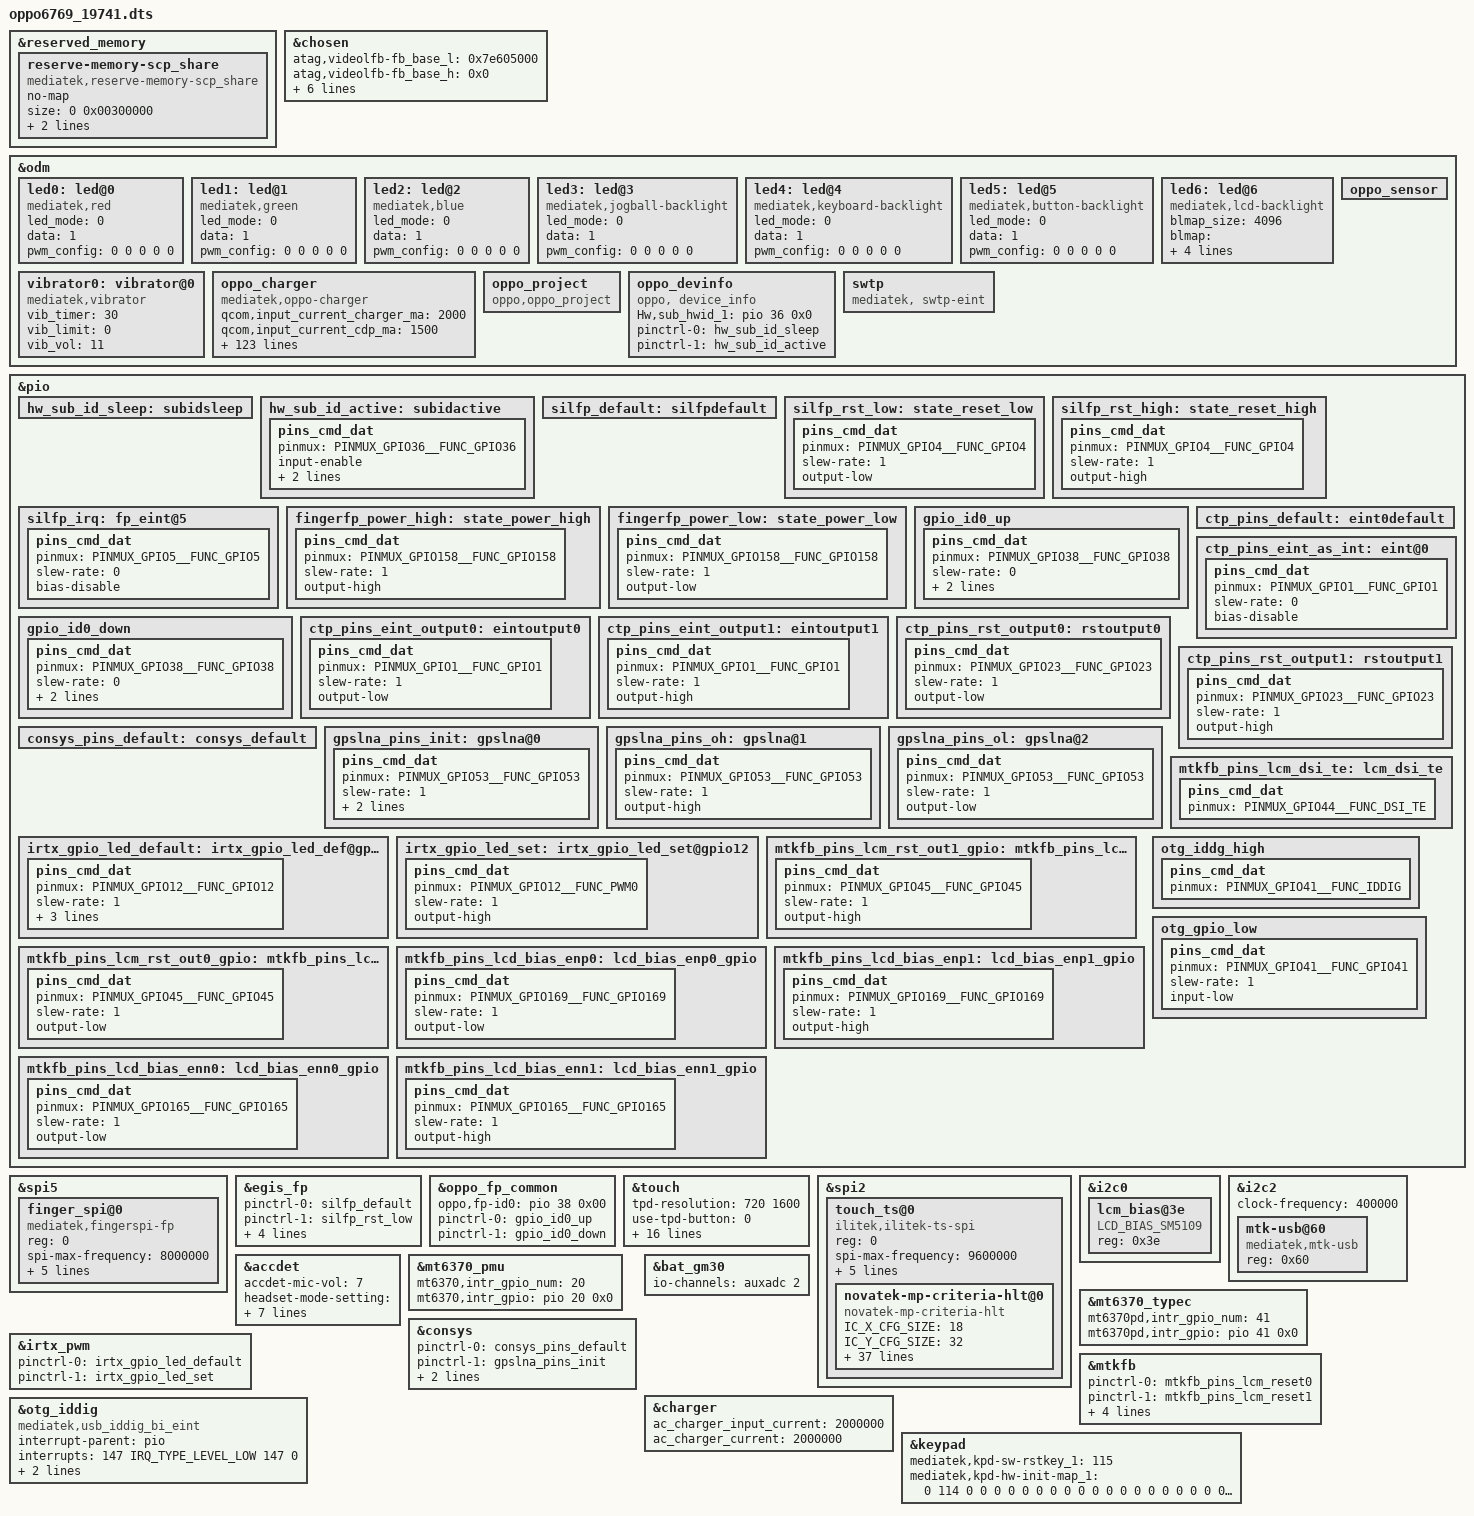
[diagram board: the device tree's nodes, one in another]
/*
 * Copyright (C) 2019 MediaTek Inc.
 *
 * This program is free software; you can redistribute it and/or modify
 * it under the terms of the GNU General Public License version 2 as
 * published by the Free Software Foundation.
 *
 * This program is distributed in the hope that it will be useful,
 * but WITHOUT ANY WARRANTY; without even the implied warranty of
 * MERCHANTABILITY or FITNESS FOR A PARTICULAR PURPOSE.
 * See http://www.gnu.org/licenses/gpl-2.0.html for more details.
 */

/dts-v1/;
/plugin/;
#include <dt-bindings/interrupt-controller/irq.h>
#include <dt-bindings/interrupt-controller/arm-gic.h>
#include <dt-bindings/pinctrl/mt6768-pinfunc.h>

&reserved_memory {
	reserve-memory-scp_share {
		compatible = "mediatek,reserve-memory-scp_share";
		no-map;
		size = <0 0x00300000>;
		alignment = <0 0x1000000>;
		alloc-ranges = <0 0x40000000 0 0x50000000>;
	};
};

/* chosen */
&chosen {

	atag,videolfb-fb_base_l = <0x7e605000>;
	atag,videolfb-fb_base_h = <0x0>;
	atag,videolfb-islcmfound = <1>;
	atag,videolfb-islcm_inited = <0>;
	atag,videolfb-fps= <6000>;
	atag,videolfb-vramSize= <0x017e8000>;
	atag,videolfb-lcmname=
		"hx83112b_fhdp_dsi_cmd_auo_rt5081_drv";
};

&odm {
	led0:led@0 {
		compatible = "mediatek,red";
		led_mode = <0>;
		data = <1>;
		pwm_config = <0 0 0 0 0>;
	};
	led1:led@1 {
		compatible = "mediatek,green";
		led_mode = <0>;
		data = <1>;
		pwm_config = <0 0 0 0 0>;
	};
	led2:led@2 {
		compatible = "mediatek,blue";
		led_mode = <0>;
		data = <1>;
		pwm_config = <0 0 0 0 0>;
	};
	led3:led@3 {
		compatible = "mediatek,jogball-backlight";
		led_mode = <0>;
		data = <1>;
		pwm_config = <0 0 0 0 0>;
	};
	led4:led@4 {
		compatible = "mediatek,keyboard-backlight";
		led_mode = <0>;
		data = <1>;
		pwm_config = <0 0 0 0 0>;
	};
	led5:led@5 {
		compatible = "mediatek,button-backlight";
		led_mode = <0>;
		data = <1>;
		pwm_config = <0 0 0 0 0>;
	};
	led6:led@6 {
		compatible = "mediatek,lcd-backlight";
		blmap_size = <4096>;
		blmap = <
			0 1 2 3 4 5 6 7 8 9 10 11 12 13
			14 17 21 26 31 38 44 51 59 67 76 85 95 105
			115 126 137 148 160 172 184 196 208 220 233 245 258 270
			283 295 307 319 331 343 355 366 377 388 398 408 418 427
			436 445 454 462 471 479 487 495 503 510 518 524 531 537
			543 548 553 557 562 565 569 573 576 580 583 586 590 593
			597 600 604 607 610 614 617 621 624 628 631 635 638 641
			645 648 652 655 658 662 665 668 672 675 678 682 685 688
			691 695 698 701 704 707 711 714 717 720 723 726 729 732
			735 738 741 744 747 750 753 756 759 762 765 768 771 774
			777 779 782 785 788 790 793 796 798 801 804 806 809 812
			814 817 819 822 824 827 829 832 834 836 839 841 843 846
			848 850 853 855 857 859 862 864 866 868 871 873 875 877
			880 882 884 886 889 891 893 895 898 900 902 904 906 908
			911 913 915 917 919 921 924 926 928 930 932 934 936 939
			941 943 945 947 949 951 953 955 958 960 962 964 966 968
			970 972 974 976 978 980 982 984 986 988 990 992 994 996
			998 1000 1002 1004 1006 1008 1010 1012 1014 1016 1018 1020 1022 1024
			1026 1028 1030 1032 1034 1036 1038 1040 1042 1044 1045 1047 1049 1051
			1053 1055 1057 1059 1061 1063 1064 1066 1068 1070 1072 1074 1076 1077
			1079 1081 1083 1085 1087 1089 1090 1092 1094 1096 1098 1099 1101 1103
			1105 1107 1109 1110 1112 1114 1116 1117 1119 1121 1123 1125 1126 1128
			1130 1132 1133 1135 1137 1139 1140 1142 1144 1146 1147 1149 1151 1152
			1154 1156 1158 1159 1161 1163 1164 1166 1168 1170 1171 1173 1175 1176
			1178 1180 1181 1183 1185 1186 1188 1190 1191 1193 1195 1196 1198 1200
			1201 1203 1204 1206 1208 1209 1211 1213 1214 1216 1217 1219 1221 1222
			1224 1226 1227 1229 1230 1232 1233 1235 1237 1238 1240 1241 1243 1245
			1246 1248 1249 1251 1252 1254 1256 1257 1259 1260 1262 1263 1265 1266
			1268 1269 1271 1272 1274 1276 1277 1279 1280 1282 1283 1285 1286 1288
			1289 1291 1292 1294 1295 1297 1298 1300 1301 1303 1304 1306 1307 1309
			1310 1312 1313 1315 1316 1318 1319 1321 1322 1323 1325 1326 1328 1329
			1331 1332 1334 1335 1337 1338 1339 1341 1342 1344 1345 1347 1348 1350
			1351 1352 1354 1355 1357 1358 1360 1361 1362 1364 1365 1367 1368 1370
			1371 1372 1374 1375 1377 1378 1379 1381 1382 1384 1385 1386 1388 1389
			1391 1392 1393 1395 1396 1398 1399 1400 1402 1403 1405 1406 1407 1409
			1410 1412 1413 1414 1416 1417 1418 1420 1421 1423 1424 1425 1427 1428
			1429 1431 1432 1433 1435 1436 1438 1439 1440 1442 1443 1444 1446 1447
			1448 1450 1451 1452 1454 1455 1457 1458 1459 1461 1462 1463 1465 1466
			1467 1469 1470 1471 1473 1474 1475 1477 1478 1479 1481 1482 1483 1485
			1486 1487 1489 1490 1491 1493 1494 1495 1497 1498 1499 1501 1502 1503
			1505 1506 1507 1509 1510 1511 1513 1514 1515 1517 1518 1519 1521 1522
			1523 1525 1526 1527 1529 1530 1531 1533 1534 1535 1537 1538 1539 1541
			1542 1543 1545 1546 1547 1549 1550 1551 1553 1554 1555 1557 1558 1559
			1561 1562 1563 1565 1566 1567 1569 1570 1571 1573 1574 1575 1577 1578
			1579 1581 1582 1583 1585 1586 1587 1589 1590 1591 1593 1594 1595 1597
			1598 1599 1601 1602 1603 1605 1606 1608 1609 1610 1612 1613 1614 1616
			1617 1618 1620 1621 1622 1624 1625 1626 1628 1629 1630 1632 1633 1635
			1636 1637 1639 1640 1641 1643 1644 1645 1647 1648 1649 1651 1652 1653
			1655 1656 1657 1658 1660 1661 1662 1663 1665 1666 1667 1668 1670 1671
			1672 1673 1674 1676 1677 1678 1679 1680 1682 1683 1684 1685 1686 1687
			1688 1690 1691 1692 1693 1694 1695 1696 1697 1699 1700 1701 1702 1703
			1704 1705 1706 1707 1708 1709 1711 1712 1713 1714 1715 1716 1717 1718
			1719 1720 1721 1722 1723 1724 1725 1726 1727 1728 1730 1731 1732 1733
			1734 1735 1736 1737 1738 1739 1740 1741 1742 1743 1744 1745 1746 1747
			1748 1749 1750 1751 1752 1753 1754 1755 1756 1757 1758 1759 1760 1761
			1762 1763 1764 1765 1767 1768 1769 1770 1771 1772 1773 1774 1775 1776
			1777 1778 1779 1780 1781 1782 1783 1784 1785 1786 1787 1789 1790 1791
			1792 1793 1794 1795 1796 1797 1798 1799 1800 1801 1802 1803 1804 1805
			1806 1808 1809 1810 1811 1812 1813 1814 1815 1816 1817 1818 1819 1820
			1821 1822 1823 1824 1825 1827 1828 1829 1830 1831 1832 1833 1834 1835
			1836 1837 1838 1839 1840 1841 1842 1843 1844 1845 1847 1848 1849 1850
			1851 1852 1853 1854 1855 1856 1857 1858 1859 1860 1861 1862 1863 1864
			1865 1866 1867 1868 1870 1871 1872 1873 1874 1875 1876 1877 1878 1879
			1880 1881 1882 1883 1884 1885 1886 1887 1888 1889 1890 1891 1892 1893
			1894 1895 1896 1897 1898 1899 1901 1902 1903 1904 1905 1906 1907 1908
			1909 1910 1911 1912 1913 1914 1915 1916 1917 1918 1919 1920 1921 1922
			1923 1924 1925 1926 1927 1928 1929 1930 1931 1932 1933 1934 1935 1936
			1937 1938 1939 1940 1941 1942 1943 1944 1945 1946 1947 1948 1949 1950
			1951 1952 1953 1954 1955 1956 1957 1958 1959 1960 1961 1962 1963 1964
			1964 1965 1966 1967 1968 1969 1970 1971 1972 1973 1974 1975 1976 1977
			1978 1979 1980 1981 1982 1983 1984 1985 1986 1986 1987 1988 1989 1990
			1991 1992 1993 1994 1995 1996 1997 1998 1999 2000 2001 2001 2002 2003
			2004 2005 2006 2007 2008 2009 2010 2011 2012 2012 2013 2014 2015 2016
			2017 2018 2019 2020 2021 2021 2022 2023 2024 2025 2026 2027 2028 2029
			2029 2030 2031 2032 2033 2034 2035 2036 2036 2037 2038 2039 2040 2041
			2042 2042 2043 2044 2045 2046 2047 2048 2048 2049 2050 2051 2052 2053
			2053 2054 2055 2056 2057 2058 2058 2059 2060 2061 2062 2062 2063 2064
			2065 2066 2067 2067 2068 2069 2070 2071 2071 2072 2073 2074 2075 2075
			2076 2077 2078 2079 2079 2080 2081 2082 2082 2083 2084 2085 2086 2086
			2087 2088 2089 2089 2090 2091 2092 2092 2093 2094 2095 2096 2096 2097
			2098 2099 2099 2100 2101 2102 2102 2103 2104 2105 2105 2106 2107 2108
			2108 2109 2110 2110 2111 2112 2113 2113 2114 2115 2116 2116 2117 2118
			2119 2119 2120 2121 2121 2122 2123 2124 2124 2125 2126 2126 2127 2128
			2129 2129 2130 2131 2131 2132 2133 2134 2134 2135 2136 2136 2137 2138
			2139 2139 2140 2141 2141 2142 2143 2144 2144 2145 2146 2146 2147 2148
			2148 2149 2150 2151 2151 2152 2153 2153 2154 2155 2155 2156 2157 2157
			2158 2159 2160 2160 2161 2162 2162 2163 2164 2164 2165 2166 2166 2167
			2168 2169 2169 2170 2171 2171 2172 2173 2173 2174 2175 2175 2176 2177
			2177 2178 2179 2179 2180 2181 2182 2182 2183 2184 2184 2185 2186 2186
			2187 2188 2188 2189 2190 2190 2191 2192 2192 2193 2194 2195 2195 2196
			2197 2197 2198 2199 2199 2200 2201 2201 2202 2203 2203 2204 2205 2206
			2206 2207 2208 2208 2209 2210 2210 2211 2212 2212 2213 2214 2215 2215
			2216 2217 2217 2218 2219 2219 2220 2221 2221 2222 2223 2224 2224 2225
			2226 2226 2227 2228 2228 2229 2230 2231 2231 2232 2233 2233 2234 2235
			2236 2236 2237 2238 2238 2239 2240 2240 2241 2242 2243 2243 2244 2245
			2245 2246 2247 2248 2248 2249 2250 2251 2251 2252 2253 2253 2254 2255
			2256 2256 2257 2258 2259 2259 2260 2261 2261 2262 2263 2264 2264 2265
			2266 2267 2267 2268 2269 2270 2270 2271 2272 2273 2273 2274 2275 2276
			2276 2277 2278 2279 2279 2280 2281 2282 2282 2283 2284 2285 2285 2286
			2287 2288 2288 2289 2290 2291 2291 2292 2293 2294 2294 2295 2296 2297
			2297 2298 2299 2300 2300 2301 2302 2303 2303 2304 2305 2306 2306 2307
			2308 2309 2309 2310 2311 2312 2313 2313 2314 2315 2316 2316 2317 2318
			2319 2319 2320 2321 2322 2322 2323 2324 2325 2326 2326 2327 2328 2329
			2329 2330 2331 2332 2332 2333 2334 2335 2336 2336 2337 2338 2339 2339
			2340 2341 2342 2342 2343 2344 2345 2346 2346 2347 2348 2349 2349 2350
			2351 2352 2353 2353 2354 2355 2356 2356 2357 2358 2359 2359 2360 2361
			2362 2363 2363 2364 2365 2366 2366 2367 2368 2369 2370 2370 2371 2372
			2373 2373 2374 2375 2376 2376 2377 2378 2379 2380 2380 2381 2382 2383
			2383 2384 2385 2386 2387 2387 2388 2389 2390 2390 2391 2392 2393 2394
			2394 2395 2396 2397 2397 2398 2399 2400 2400 2401 2402 2403 2404 2404
			2405 2406 2407 2407 2408 2409 2410 2411 2411 2412 2413 2414 2414 2415
			2416 2417 2417 2418 2419 2420 2421 2421 2422 2423 2424 2424 2425 2426
			2427 2427 2428 2429 2430 2430 2431 2432 2433 2434 2434 2435 2436 2437
			2437 2438 2439 2440 2440 2441 2442 2443 2443 2444 2445 2446 2446 2447
			2448 2449 2450 2450 2451 2452 2453 2453 2454 2455 2456 2456 2457 2458
			2459 2459 2460 2461 2462 2462 2463 2464 2465 2465 2466 2467 2468 2468
			2469 2470 2471 2471 2472 2473 2474 2474 2475 2476 2477 2477 2478 2479
			2480 2480 2481 2482 2482 2483 2484 2485 2485 2486 2487 2488 2488 2489
			2490 2491 2491 2492 2493 2493 2494 2495 2496 2496 2497 2498 2499 2499
			2500 2501 2502 2502 2503 2504 2504 2505 2506 2507 2507 2508 2509 2509
			2510 2511 2512 2512 2513 2514 2514 2515 2516 2517 2517 2518 2519 2519
			2520 2521 2522 2522 2523 2524 2524 2525 2526 2527 2527 2528 2529 2529
			2530 2531 2531 2532 2533 2534 2534 2535 2536 2536 2537 2538 2538 2539
			2540 2540 2541 2542 2542 2543 2544 2545 2545 2546 2547 2547 2548 2549
			2549 2550 2551 2551 2552 2553 2553 2554 2555 2555 2556 2557 2557 2558
			2559 2559 2560 2561 2561 2562 2563 2563 2564 2565 2565 2566 2567 2567
			2568 2569 2569 2570 2571 2571 2572 2572 2573 2574 2574 2575 2576 2576
			2577 2578 2578 2579 2580 2580 2581 2581 2582 2583 2583 2584 2585 2585
			2586 2587 2587 2588 2588 2589 2590 2590 2591 2592 2592 2593 2593 2594
			2595 2595 2596 2597 2597 2598 2598 2599 2600 2600 2601 2602 2602 2603
			2603 2604 2605 2605 2606 2607 2607 2608 2608 2609 2610 2610 2611 2611
			2612 2613 2613 2614 2615 2615 2616 2616 2617 2618 2618 2619 2619 2620
			2621 2621 2622 2622 2623 2624 2624 2625 2625 2626 2627 2627 2628 2628
			2629 2630 2630 2631 2631 2632 2633 2633 2634 2634 2635 2636 2636 2637
			2637 2638 2639 2639 2640 2640 2641 2642 2642 2643 2643 2644 2645 2645
			2646 2646 2647 2648 2648 2649 2649 2650 2650 2651 2652 2652 2653 2653
			2654 2655 2655 2656 2656 2657 2657 2658 2659 2659 2660 2660 2661 2661
			2662 2663 2663 2664 2664 2665 2666 2666 2667 2667 2668 2668 2669 2670
			2670 2671 2671 2672 2672 2673 2674 2674 2675 2675 2676 2676 2677 2677
			2678 2679 2679 2680 2680 2681 2681 2682 2683 2683 2684 2684 2685 2685
			2686 2687 2687 2688 2688 2689 2689 2690 2690 2691 2692 2692 2693 2693
			2694 2694 2695 2695 2696 2697 2697 2698 2698 2699 2699 2700 2700 2701
			2702 2702 2703 2703 2704 2704 2705 2705 2706 2706 2707 2708 2708 2709
			2709 2710 2710 2711 2711 2712 2712 2713 2714 2714 2715 2715 2716 2716
			2717 2717 2718 2718 2719 2719 2720 2721 2721 2722 2722 2723 2723 2724
			2724 2725 2725 2726 2726 2727 2728 2728 2729 2729 2730 2730 2731 2731
			2732 2732 2733 2733 2734 2734 2735 2736 2736 2737 2737 2738 2738 2739
			2739 2740 2740 2741 2741 2742 2742 2743 2743 2744 2744 2745 2745 2746
			2747 2747 2748 2748 2749 2749 2750 2750 2751 2751 2752 2752 2753 2753
			2754 2754 2755 2755 2756 2756 2757 2757 2758 2758 2759 2760 2760 2761
			2761 2762 2762 2763 2763 2764 2764 2765 2765 2766 2766 2767 2767 2768
			2768 2769 2769 2770 2770 2771 2771 2772 2772 2773 2773 2774 2774 2775
			2775 2776 2776 2777 2777 2778 2778 2779 2779 2780 2780 2781 2781 2782
			2782 2783 2783 2784 2784 2785 2785 2786 2786 2787 2787 2788 2788 2789
			2789 2790 2790 2791 2791 2792 2792 2793 2793 2794 2794 2795 2795 2796
			2796 2797 2797 2798 2798 2799 2799 2800 2800 2801 2801 2802 2802 2803
			2803 2804 2804 2805 2805 2806 2806 2807 2807 2808 2808 2809 2809 2810
			2810 2811 2811 2812 2812 2813 2813 2814 2814 2815 2815 2816 2816 2817
			2817 2818 2818 2819 2819 2819 2820 2820 2821 2821 2822 2822 2823 2823
			2824 2824 2825 2825 2826 2826 2827 2827 2828 2828 2829 2829 2830 2830
			2831 2831 2832 2832 2833 2833 2833 2834 2834 2835 2835 2836 2836 2837
			2837 2838 2838 2839 2839 2840 2840 2841 2841 2842 2842 2843 2843 2844
			2844 2844 2845 2845 2846 2846 2847 2847 2848 2848 2849 2849 2850 2850
			2851 2851 2852 2852 2853 2853 2853 2854 2854 2855 2855 2856 2856 2857
			2857 2858 2858 2859 2859 2860 2860 2861 2861 2861 2862 2862 2863 2863
			2864 2864 2865 2865 2866 2866 2867 2867 2868 2868 2869 2869 2869 2870
			2870 2871 2871 2872 2872 2873 2873 2874 2874 2875 2875 2876 2876 2876
			2877 2877 2878 2878 2879 2879 2880 2880 2881 2881 2882 2882 2882 2883
			2883 2884 2884 2885 2885 2886 2886 2887 2887 2888 2888 2889 2889 2889
			2890 2890 2891 2891 2892 2892 2893 2893 2894 2894 2895 2895 2895 2896
			2896 2897 2897 2898 2898 2899 2899 2900 2900 2900 2901 2901 2902 2902
			2903 2903 2904 2904 2905 2905 2906 2906 2906 2907 2907 2908 2908 2909
			2909 2910 2910 2911 2911 2911 2912 2912 2913 2913 2914 2914 2915 2915
			2916 2916 2917 2917 2917 2918 2918 2919 2919 2920 2920 2921 2921 2922
			2922 2922 2923 2923 2924 2924 2925 2925 2926 2926 2927 2927 2927 2928
			2928 2929 2929 2930 2930 2931 2931 2932 2932 2932 2933 2933 2934 2934
			2935 2935 2936 2936 2937 2937 2937 2938 2938 2939 2939 2940 2940 2941
			2941 2942 2942 2942 2943 2943 2944 2944 2945 2945 2946 2946 2947 2947
			2947 2948 2948 2949 2949 2950 2950 2951 2951 2952 2952 2952 2953 2953
			2954 2954 2955 2955 2956 2956 2957 2957 2957 2958 2958 2959 2959 2960
			2960 2961 2961 2961 2962 2962 2963 2963 2964 2964 2965 2965 2966 2966
			2966 2967 2967 2968 2968 2969 2969 2970 2970 2971 2971 2971 2972 2972
			2973 2973 2974 2974 2975 2975 2976 2976 2976 2977 2977 2978 2978 2979
			2979 2980 2980 2981 2981 2981 2982 2982 2983 2983 2984 2984 2985 2985
			2986 2986 2986 2987 2987 2988 2988 2989 2989 2990 2990 2990 2991 2991
			2992 2992 2993 2993 2994 2994 2995 2995 2995 2996 2996 2997 2997 2998
			2998 2999 2999 3000 3000 3000 3001 3001 3002 3002 3003 3003 3004 3004
			3005 3005 3006 3006 3006 3007 3007 3008 3008 3009 3009 3010 3010 3011
			3011 3011 3012 3012 3013 3013 3014 3014 3015 3015 3016 3016 3016 3017
			3017 3018 3018 3019 3019 3020 3020 3021 3021 3021 3022 3022 3023 3023
			3024 3024 3025 3025 3026 3026 3027 3027 3027 3028 3028 3029 3029 3030
			3030 3031 3031 3032 3032 3032 3033 3033 3034 3034 3035 3035 3036 3036
			3037 3037 3038 3038 3038 3039 3039 3040 3040 3041 3041 3042 3042 3043
			3043 3044 3044 3044 3045 3045 3046 3046 3047 3047 3048 3048 3049 3049
			3050 3050 3051 3051 3051 3052 3052 3053 3053 3054 3054 3055 3055 3056
			3056 3057 3057 3057 3058 3058 3059 3059 3060 3060 3061 3061 3062 3062
			3063 3063 3064 3064 3064 3065 3065 3066 3066 3067 3067 3068 3068 3069
			3069 3070 3070 3071 3071 3072 3072 3072 3073 3073 3074 3074 3075 3075
			3076 3076 3077 3077 3078 3078 3079 3079 3080 3080 3080 3081 3081 3082
			3082 3083 3083 3084 3084 3085 3085 3086 3086 3087 3087 3088 3088 3089
			3089 3090 3090 3090 3091 3091 3092 3092 3093 3093 3094 3094 3095 3095
			3096 3096 3097 3097 3098 3098 3099 3099 3100 3100 3101 3101 3101 3102
			3102 3103 3103 3104 3104 3105 3105 3106 3106 3107 3107 3108 3108 3109
			3109 3110 3110 3111 3111 3112 3112 3113 3113 3114 3114 3115 3115 3116
			3116 3117 3117 3117 3118 3118 3119 3119 3120 3120 3121 3121 3122 3122
			3123 3123 3124 3124 3125 3125 3126 3126 3127 3127 3128 3128 3129 3129
			3130 3130 3131 3131 3132 3132 3133 3133 3134 3134 3135 3135 3136 3136
			3137 3137 3138 3138 3139 3139 3140 3140 3141 3141 3142 3142 3143 3143
			3144 3144 3145 3145 3146 3146 3147 3147 3148 3148 3149 3149 3150 3150
			3151 3151 3152 3152 3153 3153 3154 3154 3155 3155 3156 3156 3157 3157
			3158 3158 3159 3159 3160 3160 3161 3161 3162 3162 3163 3163 3164 3164
			3165 3165 3166 3166 3167 3167 3168 3168 3169 3170 3170 3171 3171 3172
			3172 3173 3173 3174 3174 3175 3175 3176 3176 3177 3177 3178 3178 3179
			3179 3180 3180 3181 3181 3182 3182 3183 3183 3184 3185 3185 3186 3186
			3187 3187 3188 3188 3189 3189 3190 3190 3191 3191 3192 3192 3193 3193
			3194 3195 3195 3196 3196 3197 3197 3198 3198 3199 3199 3200 3200 3201
			3201 3202 3202 3203 3204 3204 3205 3205 3206 3206 3207 3207 3208 3208
			3209 3209 3210 3211 3211 3212 3212 3213 3213 3214 3214 3215 3215 3216
			3216 3217 3218 3218 3219 3219 3220 3220 3221 3221 3222 3222 3223 3224
			3224 3225 3225 3226 3226 3227 3227 3228 3228 3229 3230 3230 3231 3231
			3232 3232 3233 3233 3234 3235 3235 3236 3236 3237 3237 3238 3238 3239
			3240 3240 3241 3241 3242 3242 3243 3243 3244 3245 3245 3246 3246 3247
			3247 3248 3248 3249 3250 3250 3251 3251 3252 3252 3253 3254 3254 3255
			3255 3256 3256 3257 3258 3258 3259 3259 3260 3260 3261 3261 3262 3263
			3263 3264 3264 3265 3266 3266 3267 3267 3268 3268 3269 3270 3270 3271
			3271 3272 3272 3273 3274 3274 3275 3275 3276 3276 3277 3278 3278 3279
			3279 3280 3281 3281 3282 3282 3283 3284 3284 3285 3285 3286 3286 3287
			3288 3288 3289 3289 3290 3291 3291 3292 3292 3293 3294 3294 3295 3295
			3296 3297 3297 3298 3298 3299 3300 3300 3301 3301 3302 3303 3303 3304
			3304 3305 3306 3306 3307 3307 3308 3309 3309 3310 3310 3311 3312 3312
			3313 3313 3314 3315 3315 3316 3316 3317 3318 3318 3319 3320 3320 3321
			3321 3322 3323 3323 3324 3324 3325 3326 3326 3327 3328 3328 3329 3329
			3330 3331 3331 3332 3332 3333 3334 3334 3335 3336 3336 3337 3337 3338
			3339 3339 3340 3341 3341 3342 3343 3343 3344 3344 3345 3346 3346 3347
			3348 3348 3349 3349 3350 3351 3351 3352 3353 3353 3354 3355 3355 3356
			3357 3357 3358 3358 3359 3360 3360 3361 3362 3362 3363 3364 3364 3365
			3366 3366 3367 3368 3368 3369 3369 3370 3371 3371 3372 3373 3373 3374
			3375 3375 3376 3377 3377 3378 3379 3379 3380 3381 3381 3382 3383 3383
			3384 3385 3385 3386 3387 3387 3388 3389 3389 3390 3391 3391 3392 3393
			3393 3394 3395 3395 3396 3397 3397 3398 3399 3399 3400 3401 3401 3402
			3403 3403 3404 3405 3405 3406 3407 3407 3408 3409 3410 3410 3411 3412
			3412 3413 3414 3414 3415 3416 3416 3417 3418 3418 3419 3420 3421 3421
			3422 3423 3423 3424 3425 3425 3426 3427 3427 3428 3429 3430 3430 3431
			3432 3432 3433 3434 3434 3435 3436 3437 3437 3438 3439 3439 3440 3441
			3442 3442 3443 3444 3444 3445 3446 3447 3447 3448 3449 3449 3450 3451
			3452 3452 3453 3454 3454 3455 3456 3457 3457 3458 3459 3459 3460 3461
			3462 3462 3463 3464 3465 3465 3466 3467 3467 3468 3469 3470 3470 3471
			3472 3473 3473 3474 3475 3476 3476 3477 3478 3479 3479 3480 3481 3481
			3482 3483 3484 3484 3485 3486 3487 3487 3488 3489 3490 3490 3491 3492
			3493 3493 3494 3495 3496 3496 3497 3498 3499 3499 3500 3501 3502 3503
			3503 3504 3505 3506 3506 3507 3508 3509 3509 3510 3511 3512 3512 3513
			3514 3515 3516 3517 3518 3519 3520 3521 3522 3523 3524 3525 3526 3527
			3528 3529 3530 3531 3532 3533 3534 3535 3536 3537 3538 3539 3540 3541
			3542 3543 3544 3545 3546 3547 3548 3549 3550 3551 3552 3553 3554 3555
			3556 3557 3558 3559 3560 3561 3562 3563 3564 3565 3566 3567 3568 3569
			3570 3571 3572 3573 3574 3575 3576 3577 3578 3579 3580 3581 3582 3583
			3584 3585 3586 3587 3588 3589 3590 3591 3592 3593 3594 3595 3596 3597
			3598 3599 3600 3601 3602 3603 3604 3605 3606 3607 3608 3609 3610 3611
			3612 3613 3614 3615 3616 3617 3618 3619 3620 3621 3622 3623 3624 3625
			3626 3627 3628 3629 3630 3631 3632 3633 3634 3635 3636 3637 3638 3639
			3640 3641 3642 3643 3644 3645 3646 3647 3648 3649 3650 3651 3652 3653
			3654 3655 3656 3657 3658 3659 3660 3661 3662 3663 3664 3665 3666 3667
			3668 3669 3670 3671 3672 3673 3674 3675 3676 3677 3678 3679 3680 3681
			3682 3683 3684 3685 3686 3687 3688 3689 3690 3691 3692 3693 3694 3695
			3696 3697 3698 3699 3700 3701 3702 3703 3704 3705 3706 3707 3708 3709
			3710 3711 3712 3713 3714 3715 3716 3717 3718 3719 3720 3721 3722 3723
			3724 3725 3726 3727 3728 3729 3730 3731 3732 3733 3734 3735 3736 3737
			3738 3739 3740 3741 3742 3743 3744 3745 3746 3747 3748 3749 3750 3751
			3752 3753 3754 3755 3756 3757 3758 3759 3760 3761 3762 3763 3764 3765
			3766 3767 3768 3769 3770 3771 3772 3773 3774 3775 3776 3777 3778 3779
			3780 3781 3782 3783 3784 3785 3786 3787 3788 3789 3790 3791 3792 3793
			3794 3795 3796 3797 3798 3799 3800 3801 3802 3803 3804 3805 3806 3807
			3808 3809 3810 3811 3812 3813 3814 3815 3816 3817 3818 3819 3820 3821
			3822 3823 3824 3825 3826 3827 3828 3829 3830 3831 3832 3833 3834 3835
			3836 3837 3838 3839 3840 3841 3842 3843 3844 3845 3846 3847 3848 3849
			3850 3851 3852 3853 3854 3855 3856 3857 3858 3859 3860 3861 3862 3863
			3864 3865 3866 3867 3868 3869 3870 3871 3872 3873 3874 3875 3876 3877
			3878 3879 3880 3881 3882 3883 3884 3885 3886 3887 3888 3889 3890 3891
			3892 3893 3894 3895 3896 3897 3898 3899 3900 3901 3902 3903 3904 3905
			3906 3907 3908 3909 3910 3911 3912 3913 3914 3915 3916 3917 3918 3919
			3920 3921 3922 3923 3924 3925 3926 3927 3928 3929 3930 3931 3932 3933
			3934 3935 3936 3937 3938 3939 3940 3941 3942 3943 3944 3945 3946 3947
			3948 3949 3950 3951 3952 3953 3954 3955 3956 3957 3958 3959 3960 3961
			3962 3963 3964 3965 3966 3967 3968 3969 3970 3971 3972 3973 3974 3975
			3976 3977 3978 3979 3980 3981 3982 3983 3984 3985 3986 3987 3988 3989
			3990 3991 3992 3993 3994 3995 3996 3997 3998 3999 4000 4001 4002 4003
			4004 4005 4006 4007 4008 4009 4010 4011 4012 4013 4014 4015 4016 4017
			4018 4019 4020 4021 4022 4023 4024 4025 4026 4027 4028 4029 4030 4031
			4032 4033 4034 4035 4036 4037 4038 4039 4040 4041 4042 4043 4044 4045
			4046 4047 4048 4049 4050 4051 4052 4053 4054 4055 4056 4057 4058 4059
			4060 4061 4062 4063 4064 4065 4066 4067 4068 4069 4070 4071 4072 4073
			4074 4075 4076 4077 4078 4079 4080 4081 4082 4083 4084 4085 4086 4087
			4088 4089 4090 4091 4092 4093 4094 4095
		>;
		led_mode = <4>;
		data = <1>;
		pwm_config = <0 3 0 0 0>;
	};
	vibrator0:vibrator@0 {
		compatible = "mediatek,vibrator";
		/*
		vib_timer = <25>;
		vib_limit = <9>;
		vib_vol= <9>;
		*/
		vib_timer = <30>; /*xing.xiong@BSP.Kernel.Driver, 2018/12/08, Add for vibrator*/
		vib_limit = <0>;
		vib_vol= <11>;
	};
//#ifdef ODM_WT_EDIT
/*Sidong.Zhao@ODM_WT.BSP.CHG 2019/11/4,add oppo charge framework*/
	oppo_charger: oppo_charger {
		compatible = "mediatek,oppo-charger";
		//pinctrl-names = "default", "charger_gpio_as_output_low", "charger_gpio_as_output_high", "ship_sleep", "ship_active", "shortc_active";
		//pinctrl-0 = <&charger_pins_default>;
		//pinctrl-1 = <&charger_pins_eint_output0>;
		//pinctrl-2 = <&charger_pins_eint_output1>;
		//pinctrl-3 = <&ship_sleep_gpio>;
		//pinctrl-4 = <&ship_active_gpio>;
		//pinctrl-5 = <&shortc_active_gpio>;

		//for oppo chg framework:
		qcom,input_current_charger_ma = <2000>;
		qcom,input_current_cdp_ma = <1500>;
		qcom,input_current_usb_ma = <500>;
		qcom,input_current_led_ma = <1200>;
		qcom,input_current_led_ma_forcmcc = <500>;
		qcom,input_current_camera_ma = <1200>;
		qcom,input_current_calling_ma = <1200>;
		
		qcom,input_current_led_ma_high = <1200>;
		qcom,input_current_led_ma_warm = <1500>;
		qcom,input_current_led_ma_normal = <2000>;

		qcom,led_high_bat_decidegc = <370>;
		qcom,led_warm_bat_decidegc = <350>;

		qcom,iterm_disabled = <0>;
		qcom,iterm_ma = <265>;
		qcom,recharge-mv = <115>;

		qcom,batt_capacity_mah = <5000>; /*typical capacity*/
		//qcom,batt_capacity_mah = <3900>; /*rated capacity*/

		qcom,removed_bat_decidegc = <190>;  /* < -19C */

		qcom,cold_bat_decidegc = <20>;  /* -2C ~ 0C */
		qcom,temp_cold_vfloat_mv = <3980>;
		qcom,temp_cold_fastchg_current_ma = <350>;

		qcom,little_cold_bat_decidegc = <0>;	/* 0C ~ 5C */
		qcom,temp_little_cold_vfloat_mv = <4435>;
		qcom,temp_little_cold_fastchg_current_ma_high = <650>;
		qcom,temp_little_cold_fastchg_current_ma_low = <650>;
		qcom,temp_little_cold_fastchg_current_ma = <650>;
		monet,temp_little_cold_usbchg_current_ma_high = <650>;
		monet,temp_little_cold_usbchg_current_ma_low = <650>;
		monet,temp_little_cold_usbchg_current_ma = <650>;

		qcom,cool_bat_decidegc = <50>;	/* 5C ~ 12C */
		qcom,temp_cool_vfloat_mv = <4435>;
		qcom,temp_cool_fastchg_current_ma_high = <1350>;
		qcom,temp_cool_fastchg_current_ma_low = <650>;
		monet,temp_cool_usbchg_current_ma_high = <650>;
		monet,temp_cool_usbchg_current_ma_low = <550>;

		qcom,little_cool_bat_decidegc = <120>;	/* 12C ~ 16C */
		qcom,temp_little_cool_vfloat_mv = <4435>;
		qcom,temp_little_cool_fastchg_current_ma = <2050>;
		monet,temp_little_cool_usbchg_current_ma = <550>;

		qcom,normal_bat_decidegc = <160>;	/* 16C ~ 45C */
		qcom,temp_normal_fastchg_current_ma = <2200>;
		monet,temp_normal_usbchg_current_ma = <550>;
		qcom,temp_normal_vfloat_mv = <4435>;

		qcom,warm_bat_decidegc = <440>;		/* 44C ~ 53C */ /*8pin Bat Vooc project need add 3 degree C*/
		qcom,temp_warm_vfloat_mv = <4130>;
		qcom,temp_warm_fastchg_current_ma = <1350>;
		monet,temp_warm_usbchg_current_ma = <550>;
		qcom,temp_warm_fastchg_current_ma_led_on = <500>;

		qcom,hot_bat_decidegc = <530>;  /* > 53C */

		qcom,non_standard_vfloat_mv = <3980>;
		qcom,non_standard_fastchg_current_ma = <512>;

		qcom,short_c_bat_cv_mv = <4330>;
		qcom,short_c_bat_vfloat_mv = <3800>;
		qcom,short_c_bat_fastchg_current_ma = <512>;
		qcom,short_c_bat_vfloat_sw_limit = <3750>;

		qcom,cold_vfloat_sw_limit = <3930>;
		qcom,little_cold_vfloat_sw_limit = <4380>;
		qcom,cool_vfloat_sw_limit = <4380>;
		qcom,little_cool_vfloat_sw_limit = <4380>;
		qcom,normal_vfloat_sw_limit = <4380>;
		qcom,warm_vfloat_sw_limit = <4080>;
		qcom,non_standard_vfloat_sw_limit = <3930>;

		qcom,max_chg_time_sec = <36000>;
		qcom,charger_hv_thr = <5800>;
		qcom,charger_recv_thr = <5800>;
		qcom,charger_lv_thr = <3400>;
		qcom,vbatt_full_thr = <4400>;
		qcom,vbatt_hv_thr = <4550>;

		qcom,vfloat_step_mv = <10>;
		qcom,non_standard_vfloat_over_sw_limit = <4000>;
		qcom,cold_vfloat_over_sw_limit = <4000>;
		qcom,little_cold_vfloat_over_sw_limit = <4450>;
		qcom,cool_vfloat_over_sw_limit = <4450>;
		qcom,little_cool_vfloat_over_sw_limit = <4450>;
		qcom,normal_vfloat_over_sw_limit = <4450>;
		qcom,warm_vfloat_over_sw_limit = <4150>;

		qcom,vbatt_power_off = <3300>;
		qcom,vbatt_soc_1 = <3410>;
		qcom,vooc_project = <0>;
		qcom,vbatt_num = <1>;

		qcom,normal_vterm_hw_inc = <150>;
		qcom,non_normal_vterm_hw_inc = <10>;

		qcom,ff1_normal_fastchg_ma = <1088>;
		qcom,ffc2_normal_fastchg_ma = <780>;/*16C~35c*/
		qcom,ffc2_temp_warm_decidegc = <350>;
		qcom,ffc2_warm_fastchg_ma = <840>;/*35C~40c*/
		qcom,ffc2_temp_high_decidegc = <400>;
		qcom,ffc2_temp_low_decidegc = <120>;
		qcom,ff1_exit_step_ma = <488>;
		qcom,ff1_warm_exit_step_ma = <418>;
		qcom,ffc2_exit_step_ma = <180>;
		qcom,ffc2_warm_exit_step_ma = <170>;

		qcom,ffc_normal_vfloat_sw_limit = <4430>;
		qcom,ffc_temp_normal_vfloat_mv = <4500>;
		qcom,ffc_normal_vfloat_over_sw_limit = <4500>;

		qcom,default_iterm_ma = <265>;
		qcom,default_temp_normal_fastchg_current_ma = <2200>;
		qcom,default_normal_vfloat_sw_limit = <4380>;
		qcom,default_temp_normal_vfloat_mv = <4435>;
		qcom,default_normal_vfloat_over_sw_limit = <4450>;

		//for 2nd chip:
		qcom,iterm_ma_2nd = <300>;
		qcom,recharge-mv_2nd = <121>;

		qcom,temp_little_cold_vfloat_mv_2nd = <4391>;	/* 0C ~ 5C */
		qcom,temp_cool_vfloat_mv_2nd = <4391>;	/* 5C ~ 12C */
		qcom,temp_little_cool_vfloat_mv_2nd = <4391>;	/* 12C ~ 16C */
		qcom,temp_normal_vfloat_mv_2nd = <4391>;	/* 16C ~ 45C */

		qcom,little_cold_vfloat_over_sw_limit_2nd = <4395>;
		qcom,cool_vfloat_over_sw_limit_2nd = <4395>;
		qcom,little_cool_vfloat_over_sw_limit_2nd = <4395>;
		qcom,normal_vfloat_over_sw_limit_2nd = <4395>;

		qcom,default_iterm_ma_2nd = <300>;
		qcom,default_temp_normal_vfloat_mv_2nd = <4391>;
		qcom,default_normal_vfloat_over_sw_limit_2nd = <4395>;

		//for control:
		//qcom,suspend_after_full;
		qcom,check_batt_full_by_sw;
		//qcom,external_gauge;
		qcom,chg_ctrl_by_calling;
		qcom,chg_ctrl_by_lcd;
		qcom,chg_ctrl_by_camera;
		qcom,sw_vfloat_over_protect_enable;
		//qcom,ffc_support;

		//GPIO config:
		//qcom,chargerid_switch-gpio = <&pio 97 0x00>;
		//qcom,ship-gpio = <&pio 155 0x00>;
		//qcom,shortc-gpio = <&pio 77 0x00>;
	};
//#endif /*ODM_WT_EDIT*/
//#ifdef VENDOR_EDIT
/*Bin.Li@EXP.BSP.bootloader.bootflow, 2017/05/15, Add for oppo project */
	oppo_project:oppo_project {
		compatible = "oppo,oppo_project";
	};
//#endif /*VENDOR_EDIT*/
//#ifdef VENDOR_EDIT
/*Fei.Mo@PSW.BSP.Sensor, 2017/12/18, Add for sensor calibration paramaters */
       oppo_sensor:oppo_sensor {
       };
//#endif /*VENDOR_EDIT*

//#ifdef ODM_WT_EDIT
/*Junbo.Guo@ODM_WT.BSP.Kernel.Boot, 2019/10/29, Add for hardware id */
	oppo_devinfo:oppo_devinfo {
		compatible = "oppo, device_info";
		Hw,sub_hwid_1 =<&pio 36 0x0>;
		pinctrl-names = "hw_sub_id_sleep", "hw_sub_id_active";
		pinctrl-0 = <&hw_sub_id_sleep>;
		pinctrl-1 = <&hw_sub_id_active>;
		status = "okay";
	};
//#endif /*ODM_WT_EDIT*	
//#ifdef ODM_WT_EDIT
/*Yong.Cheng@ODM_WT.NW.RF.swtp, 2019/12/10, Add for swtp, RF cable detect */
	swtp:swtp {
		compatible = "mediatek, swtp-eint";
	};
//#endif /*ODM_WT_EDIT*	/
};

//#ifdef ODM_WT_EDIT
/*Junbo.Guo@ODM_WT.BSP.Kernel.Boot, 2019/10/29, Add for hardware id */
&pio{
	hw_sub_id_sleep: subidsleep {
	};
	hw_sub_id_active: subidactive {
		pins_cmd_dat {
			pinmux = <PINMUX_GPIO36__FUNC_GPIO36>;
			input-enable;
			slew-rate = <0>;
			bias-disable;
		};
	};
};
//#endif /*ODM_WT_EDIT*

//#ifdef VENDOR_EDIT
//Qingwen.Liu@RM.BSP.Fingerprint.Basic 2019/1/26 add for fpc fingerprint driver start
&spi5 {
	#address-cells = <1>;
	#size-cells = <0>;
	status = "okay";
	finger_spi@0 {
	    compatible = "mediatek,fingerspi-fp";
	    reg = <0>;
	    spi-max-frequency = <8000000>;
	    netlink-event = <30>;
	    spi-id = <1>;
	    spi-irq = <5>;
	    spi-reg = <0x11015000>;
	    spi-avdd-gpio = <158>;
        status = "okay";
    };
};

&egis_fp {
	pinctrl-names = "default", "rst-low", "rst-high",
	                "irq-init", "power_high","power_low";
	pinctrl-0 = <&silfp_default>;
	pinctrl-1 = <&silfp_rst_low>;
	pinctrl-2 = <&silfp_rst_high>;
	pinctrl-3 = <&silfp_irq>;
	pinctrl-4 = <&fingerfp_power_high>;
	pinctrl-5 = <&fingerfp_power_low>;
	status = "okay";
};

&pio {
	silfp_default: silfpdefault {
	};
	silfp_rst_low: state_reset_low {
		pins_cmd_dat {
			pinmux = <PINMUX_GPIO4__FUNC_GPIO4>;
			slew-rate = <1>;
			output-low;
		};
	};
	silfp_rst_high: state_reset_high {
		pins_cmd_dat {
			pinmux = <PINMUX_GPIO4__FUNC_GPIO4>;
			slew-rate = <1>;
			output-high;
		};
	};
	silfp_irq: fp_eint@5 {
		pins_cmd_dat {
			pinmux = <PINMUX_GPIO5__FUNC_GPIO5>;
			slew-rate = <0>;
			bias-disable;
		};
	};
	fingerfp_power_high: state_power_high {
		pins_cmd_dat {
			pinmux = <PINMUX_GPIO158__FUNC_GPIO158>;
			slew-rate = <1>;
			output-high;
		};
	};

	fingerfp_power_low: state_power_low {
		pins_cmd_dat {
			pinmux = <PINMUX_GPIO158__FUNC_GPIO158>;
			slew-rate = <1>;
			output-low;
		};
	};
};

/*the id config to project dts.*/
&pio{
	gpio_id0_up: gpio_id0_up {
		pins_cmd_dat {
			pinmux = <PINMUX_GPIO38__FUNC_GPIO38>;
			slew-rate = <0>;
			bias-pull-up;
			input-enable;
		};
	};
	gpio_id0_down: gpio_id0_down {
		pins_cmd_dat {
			pinmux = <PINMUX_GPIO38__FUNC_GPIO38>;
			slew-rate = <0>;
			bias-pull-down;
			input-enable;
		};
	};
};

&oppo_fp_common {
	oppo,fp-id0 = <&pio 38 0x00>;
	pinctrl-names = "gpio_id0_up","gpio_id0_down";
	pinctrl-0 = <&gpio_id0_up>;
	pinctrl-1 = <&gpio_id0_down>;
	status = "okay";
};
//Qingwen.Liu@RM.BSP.Fingerprint.Basic 2019/1/26 add for fpc fingerprint driver end
//#endif //VENDOR_EDIT

/* TOUCH start */
&touch {
	tpd-resolution = <720 1600>;
	use-tpd-button = <0>;
	tpd-key-num = <3>;
	tpd-key-local= <139 172 158 0>;
	tpd-key-dim-local = <90 883 100 40 230
				883 100 40 370 883 100 40 0 0 0 0>;
	tpd-max-touch-num = <10>;
	tpd-filter-enable = <0>;
	tpd-filter-pixel-density = <168>;
	tpd-filter-custom-prameters = <0 0 0 0 0 0 0 0 0 0 0 0>;
	tpd-filter-custom-speed = <0 0 0>;
	pinctrl-names = "default", "state_eint_as_int",
		"state_eint_output0", "state_eint_output1",
		"state_rst_output0", "state_rst_output1";
	pinctrl-0 = <&ctp_pins_default>;
	pinctrl-1 = <&ctp_pins_eint_as_int>;
	pinctrl-2 = <&ctp_pins_eint_output0>;
	pinctrl-3 = <&ctp_pins_eint_output1>;
	pinctrl-4 = <&ctp_pins_rst_output0>;
	pinctrl-5 = <&ctp_pins_rst_output1>;
	status = "okay";
};
&pio {
	ctp_pins_default: eint0default {
	};
	ctp_pins_eint_as_int: eint@0 {
		pins_cmd_dat {
			pinmux = <PINMUX_GPIO1__FUNC_GPIO1>;
			slew-rate = <0>;
			bias-disable;
		};
	};
	ctp_pins_eint_output0: eintoutput0 {
		pins_cmd_dat {
			pinmux = <PINMUX_GPIO1__FUNC_GPIO1>;
			slew-rate = <1>;
			output-low;
		};
	};
	ctp_pins_eint_output1: eintoutput1 {
		pins_cmd_dat {
			pinmux = <PINMUX_GPIO1__FUNC_GPIO1>;
			slew-rate = <1>;
			output-high;
	};
	};
	ctp_pins_rst_output0: rstoutput0 {
		pins_cmd_dat {
			pinmux = <PINMUX_GPIO23__FUNC_GPIO23>;
			slew-rate = <1>;
			output-low;
		};
	};
	ctp_pins_rst_output1: rstoutput1 {
		pins_cmd_dat {
			pinmux = <PINMUX_GPIO23__FUNC_GPIO23>;
			slew-rate = <1>;
			output-high;
		};
	};
};
//#ifdef ODM_WT_EDIT
//#Tongxing.Liu@ODM_WT.BSP.Touchscreen.Base,2019/10/04,bringup add for xl and hlt touchscreen mould dts config.
&spi2 {
    #address-cells = <1>;
    #size-cells = <0>;
    touch_ts@0 {
        reg = <0>;
        compatible = "ilitek,ilitek-ts-spi","novatek,NVT-ts-spi";
	status = "okay";
	/* touch spi config */
        spi-max-frequency = <9600000>;
	/* novatek touch gpio config */
	novatek,irq-gpio = <&pio 1 0>;
	novatek,reset-gpio = <&pio 23 0>;
	novatek,reset_global_gpio = <&pio 45 0>;
	/* 672A, 525B */
	novatek,swrst-n8-addr = <0x03F0FE>;
	/* MP config  */
	novatek,mp-support-dt;
	novatek-mp-criteria-hlt@0 {
		#address-cells = <1>;
		#size-cells = <0>;
		compatible = "novatek-mp-criteria-hlt";
	        /* MP Config */
		IC_X_CFG_SIZE = <18>;
		IC_Y_CFG_SIZE = <32>;
		IC_KEY_CFG_SIZE = <4>;
		X_Channel = <18>;
		Y_Channel = <32>;
		AIN_X = <0 1 2 3 4 5 6 7 8 9 10 11 12 13 14 15 16 17>;
		AIN_Y = <0 1 2 3 4 5 6 7 8 9 10 11 12 13 14 15 16 17 18 19
							20 21 22 23 24 25 26 27 28 29 30 31>;
		AIN_KEY = <0 1 2 0xFF>;

		/* MP Criteria */
		PS_Config_Lmt_Short_Rawdata_P = <
			14008 14008 14008 14008 14008 14008 14008 14008 14008 14008 14008 14008 14008 14008 14008 14008 14008 14008
			14008 14008 14008 14008 14008 14008 14008 14008 14008 14008 14008 14008 14008 14008 14008 14008 14008 14008
			14008 14008 14008 14008 14008 14008 14008 14008 14008 14008 14008 14008 14008 14008 14008 14008 14008 14008
			14008 14008 14008 14008 14008 14008 14008 14008 14008 14008 14008 14008 14008 14008 14008 14008 14008 14008
			14008 14008 14008 14008 14008 14008 14008 14008 14008 14008 14008 14008 14008 14008 14008 14008 14008 14008
			14008 14008 14008 14008 14008 14008 14008 14008 14008 14008 14008 14008 14008 14008 14008 14008 14008 14008
			14008 14008 14008 14008 14008 14008 14008 14008 14008 14008 14008 14008 14008 14008 14008 14008 14008 14008
			14008 14008 14008 14008 14008 14008 14008 14008 14008 14008 14008 14008 14008 14008 14008 14008 14008 14008
			14008 14008 14008 14008 14008 14008 14008 14008 14008 14008 14008 14008 14008 14008 14008 14008 14008 14008
			14008 14008 14008 14008 14008 14008 14008 14008 14008 14008 14008 14008 14008 14008 14008 14008 14008 14008
			14008 14008 14008 14008 14008 14008 14008 14008 14008 14008 14008 14008 14008 14008 14008 14008 14008 14008
			14008 14008 14008 14008 14008 14008 14008 14008 14008 14008 14008 14008 14008 14008 14008 14008 14008 14008
			14008 14008 14008 14008 14008 14008 14008 14008 14008 14008 14008 14008 14008 14008 14008 14008 14008 14008
			14008 14008 14008 14008 14008 14008 14008 14008 14008 14008 14008 14008 14008 14008 14008 14008 14008 14008
			14008 14008 14008 14008 14008 14008 14008 14008 14008 14008 14008 14008 14008 14008 14008 14008 14008 14008
			14008 14008 14008 14008 14008 14008 14008 14008 14008 14008 14008 14008 14008 14008 14008 14008 14008 14008
			14008 14008 14008 14008 14008 14008 14008 14008 14008 14008 14008 14008 14008 14008 14008 14008 14008 14008
			14008 14008 14008 14008 14008 14008 14008 14008 14008 14008 14008 14008 14008 14008 14008 14008 14008 14008
			14008 14008 14008 14008 14008 14008 14008 14008 14008 14008 14008 14008 14008 14008 14008 14008 14008 14008
			14008 14008 14008 14008 14008 14008 14008 14008 14008 14008 14008 14008 14008 14008 14008 14008 14008 14008
			14008 14008 14008 14008 14008 14008 14008 14008 14008 14008 14008 14008 14008 14008 14008 14008 14008 14008
			14008 14008 14008 14008 14008 14008 14008 14008 14008 14008 14008 14008 14008 14008 14008 14008 14008 14008
			14008 14008 14008 14008 14008 14008 14008 14008 14008 14008 14008 14008 14008 14008 14008 14008 14008 14008
			14008 14008 14008 14008 14008 14008 14008 14008 14008 14008 14008 14008 14008 14008 14008 14008 14008 14008
			14008 14008 14008 14008 14008 14008 14008 14008 14008 14008 14008 14008 14008 14008 14008 14008 14008 14008
			14008 14008 14008 14008 14008 14008 14008 14008 14008 14008 14008 14008 14008 14008 14008 14008 14008 14008
			14008 14008 14008 14008 14008 14008 14008 14008 14008 14008 14008 14008 14008 14008 14008 14008 14008 14008
			14008 14008 14008 14008 14008 14008 14008 14008 14008 14008 14008 14008 14008 14008 14008 14008 14008 14008
			14008 14008 14008 14008 14008 14008 14008 14008 14008 14008 14008 14008 14008 14008 14008 14008 14008 14008
			14008 14008 14008 14008 14008 14008 14008 14008 14008 14008 14008 14008 14008 14008 14008 14008 14008 14008
			14008 14008 14008 14008 14008 14008 14008 14008 14008 14008 14008 14008 14008 14008 14008 14008 14008 14008
			14008 14008 14008 14008 14008 14008 14008 14008 14008 14008 14008 14008 14008 14008 14008 14008 14008 14008
			>;

		PS_Config_Lmt_Short_Rawdata_N = <
			10000 10000 10000 10000 10000 10000 10000 10000 10000 10000 10000 10000 10000 10000 10000 10000 10000 10000
			10000 10000 10000 10000 10000 10000 10000 10000 10000 10000 10000 10000 10000 10000 10000 10000 10000 10000
			10000 10000 10000 10000 10000 10000 10000 10000 10000 10000 10000 10000 10000 10000 10000 10000 10000 10000
			10000 10000 10000 10000 10000 10000 10000 10000 10000 10000 10000 10000 10000 10000 10000 10000 10000 10000
			10000 10000 10000 10000 10000 10000 10000 10000 10000 10000 10000 10000 10000 10000 10000 10000 10000 10000
			10000 10000 10000 10000 10000 10000 10000 10000 10000 10000 10000 10000 10000 10000 10000 10000 10000 10000
			10000 10000 10000 10000 10000 10000 10000 10000 10000 10000 10000 10000 10000 10000 10000 10000 10000 10000
			10000 10000 10000 10000 10000 10000 10000 10000 10000 10000 10000 10000 10000 10000 10000 10000 10000 10000
			10000 10000 10000 10000 10000 10000 10000 10000 10000 10000 10000 10000 10000 10000 10000 10000 10000 10000
			10000 10000 10000 10000 10000 10000 10000 10000 10000 10000 10000 10000 10000 10000 10000 10000 10000 10000
			10000 10000 10000 10000 10000 10000 10000 10000 10000 10000 10000 10000 10000 10000 10000 10000 10000 10000
			10000 10000 10000 10000 10000 10000 10000 10000 10000 10000 10000 10000 10000 10000 10000 10000 10000 10000
			10000 10000 10000 10000 10000 10000 10000 10000 10000 10000 10000 10000 10000 10000 10000 10000 10000 10000
			10000 10000 10000 10000 10000 10000 10000 10000 10000 10000 10000 10000 10000 10000 10000 10000 10000 10000
			10000 10000 10000 10000 10000 10000 10000 10000 10000 10000 10000 10000 10000 10000 10000 10000 10000 10000
			10000 10000 10000 10000 10000 10000 10000 10000 10000 10000 10000 10000 10000 10000 10000 10000 10000 10000
			10000 10000 10000 10000 10000 10000 10000 10000 10000 10000 10000 10000 10000 10000 10000 10000 10000 10000
			10000 10000 10000 10000 10000 10000 10000 10000 10000 10000 10000 10000 10000 10000 10000 10000 10000 10000
			10000 10000 10000 10000 10000 10000 10000 10000 10000 10000 10000 10000 10000 10000 10000 10000 10000 10000
			10000 10000 10000 10000 10000 10000 10000 10000 10000 10000 10000 10000 10000 10000 10000 10000 10000 10000
			10000 10000 10000 10000 10000 10000 10000 10000 10000 10000 10000 10000 10000 10000 10000 10000 10000 10000
			10000 10000 10000 10000 10000 10000 10000 10000 10000 10000 10000 10000 10000 10000 10000 10000 10000 10000
			10000 10000 10000 10000 10000 10000 10000 10000 10000 10000 10000 10000 10000 10000 10000 10000 10000 10000
			10000 10000 10000 10000 10000 10000 10000 10000 10000 10000 10000 10000 10000 10000 10000 10000 10000 10000
			10000 10000 10000 10000 10000 10000 10000 10000 10000 10000 10000 10000 10000 10000 10000 10000 10000 10000
			10000 10000 10000 10000 10000 10000 10000 10000 10000 10000 10000 10000 10000 10000 10000 10000 10000 10000
			10000 10000 10000 10000 10000 10000 10000 10000 10000 10000 10000 10000 10000 10000 10000 10000 10000 10000
			10000 10000 10000 10000 10000 10000 10000 10000 10000 10000 10000 10000 10000 10000 10000 10000 10000 10000
			10000 10000 10000 10000 10000 10000 10000 10000 10000 10000 10000 10000 10000 10000 10000 10000 10000 10000
			10000 10000 10000 10000 10000 10000 10000 10000 10000 10000 10000 10000 10000 10000 10000 10000 10000 10000
			10000 10000 10000 10000 10000 10000 10000 10000 10000 10000 10000 10000 10000 10000 10000 10000 10000 10000
			10000 10000 10000 10000 10000 10000 10000 10000 10000 10000 10000 10000 10000 10000 10000 10000 10000 10000
			>;

		PS_Config_Lmt_Open_Rawdata_P = <
			4096 4096 4096 4096 4096 4096 4096 4096 4096 4096 4096 4096 4096 4096 4096 4096 4096 4096
			4096 4096 4096 4096 4096 4096 4096 4096 4096 4096 4096 4096 4096 4096 4096 4096 4096 4096
			4096 4096 4096 4096 4096 4096 4096 4096 4096 4096 4096 4096 4096 4096 4096 4096 4096 4096
			4096 4096 4096 4096 4096 4096 4096 4096 4096 4096 4096 4096 4096 4096 4096 4096 4096 4096
			4096 4096 4096 4096 4096 4096 4096 4096 4096 4096 4096 4096 4096 4096 4096 4096 4096 4096
			4096 4096 4096 4096 4096 4096 4096 4096 4096 4096 4096 4096 4096 4096 4096 4096 4096 4096
			4096 4096 4096 4096 4096 4096 4096 4096 4096 4096 4096 4096 4096 4096 4096 4096 4096 4096
			4096 4096 4096 4096 4096 4096 4096 4096 4096 4096 4096 4096 4096 4096 4096 4096 4096 4096
			4096 4096 4096 4096 4096 4096 4096 4096 4096 4096 4096 4096 4096 4096 4096 4096 4096 4096
			4096 4096 4096 4096 4096 4096 4096 4096 4096 4096 4096 4096 4096 4096 4096 4096 4096 4096
			4096 4096 4096 4096 4096 4096 4096 4096 4096 4096 4096 4096 4096 4096 4096 4096 4096 4096
			4096 4096 4096 4096 4096 4096 4096 4096 4096 4096 4096 4096 4096 4096 4096 4096 4096 4096
			4096 4096 4096 4096 4096 4096 4096 4096 4096 4096 4096 4096 4096 4096 4096 4096 4096 4096
			4096 4096 4096 4096 4096 4096 4096 4096 4096 4096 4096 4096 4096 4096 4096 4096 4096 4096
			4096 4096 4096 4096 4096 4096 4096 4096 4096 4096 4096 4096 4096 4096 4096 4096 4096 4096
			4096 4096 4096 4096 4096 4096 4096 4096 4096 4096 4096 4096 4096 4096 4096 4096 4096 4096
			4096 4096 4096 4096 4096 4096 4096 4096 4096 4096 4096 4096 4096 4096 4096 4096 4096 4096
			4096 4096 4096 4096 4096 4096 4096 4096 4096 4096 4096 4096 4096 4096 4096 4096 4096 4096
			4096 4096 4096 4096 4096 4096 4096 4096 4096 4096 4096 4096 4096 4096 4096 4096 4096 4096
			4096 4096 4096 4096 4096 4096 4096 4096 4096 4096 4096 4096 4096 4096 4096 4096 4096 4096
			4096 4096 4096 4096 4096 4096 4096 4096 4096 4096 4096 4096 4096 4096 4096 4096 4096 4096
			4096 4096 4096 4096 4096 4096 4096 4096 4096 4096 4096 4096 4096 4096 4096 4096 4096 4096
			4096 4096 4096 4096 4096 4096 4096 4096 4096 4096 4096 4096 4096 4096 4096 4096 4096 4096
			4096 4096 4096 4096 4096 4096 4096 4096 4096 4096 4096 4096 4096 4096 4096 4096 4096 4096
			4096 4096 4096 4096 4096 4096 4096 4096 4096 4096 4096 4096 4096 4096 4096 4096 4096 4096
			4096 4096 4096 4096 4096 4096 4096 4096 4096 4096 4096 4096 4096 4096 4096 4096 4096 4096
			4096 4096 4096 4096 4096 4096 4096 4096 4096 4096 4096 4096 4096 4096 4096 4096 4096 4096
			4096 4096 4096 4096 4096 4096 4096 4096 4096 4096 4096 4096 4096 4096 4096 4096 4096 4096
			4096 4096 4096 4096 4096 4096 4096 4096 4096 4096 4096 4096 4096 4096 4096 4096 4096 4096
			4096 4096 4096 4096 4096 4096 4096 4096 4096 4096 4096 4096 4096 4096 4096 4096 4096 4096
			4096 4096 4096 4096 4096 4096 4096 4096 4096 4096 4096 4096 4096 4096 4096 4096 4096 4096
			4096 4096 4096 4096 4096 4096 4096 4096 4096 4096 4096 4096 4096 4096 4096 4096 4096 4096
			>;

		PS_Config_Lmt_Open_Rawdata_N = <
			50 50 50 50 50 50 50 50 50 50 50 50 50 50 50 50 50 50
			50 50 50 50 50 50 50 50 50 50 50 50 50 50 50 50 50 50
			50 50 50 50 50 50 50 50 50 50 50 50 50 50 50 50 50 50
			50 50 50 50 50 50 50 50 50 50 50 50 50 50 50 50 50 50
			50 50 50 50 50 50 50 50 50 50 50 50 50 50 50 50 50 50
			50 50 50 50 50 50 50 50 50 50 50 50 50 50 50 50 50 50
			50 50 50 50 50 50 50 50 50 50 50 50 50 50 50 50 50 50
			50 50 50 50 50 50 50 50 50 50 50 50 50 50 50 50 50 50
			50 50 50 50 50 50 50 50 50 50 50 50 50 50 50 50 50 50
			50 50 50 50 50 50 50 50 50 50 50 50 50 50 50 50 50 50
			50 50 50 50 50 50 50 50 50 50 50 50 50 50 50 50 50 50
			50 50 50 50 50 50 50 50 50 50 50 50 50 50 50 50 50 50
			50 50 50 50 50 50 50 50 50 50 50 50 50 50 50 50 50 50
			50 50 50 50 50 50 50 50 50 50 50 50 50 50 50 50 50 50
			50 50 50 50 50 50 50 50 50 50 50 50 50 50 50 50 50 50
			50 50 50 50 50 50 50 50 50 50 50 50 50 50 50 50 50 50
			50 50 50 50 50 50 50 50 50 50 50 50 50 50 50 50 50 50
			50 50 50 50 50 50 50 50 50 50 50 50 50 50 50 50 50 50
			50 50 50 50 50 50 50 50 50 50 50 50 50 50 50 50 50 50
			50 50 50 50 50 50 50 50 50 50 50 50 50 50 50 50 50 50
			50 50 50 50 50 50 50 50 50 50 50 50 50 50 50 50 50 50
			50 50 50 50 50 50 50 50 50 50 50 50 50 50 50 50 50 50
			50 50 50 50 50 50 50 50 50 50 50 50 50 50 50 50 50 50
			50 50 50 50 50 50 50 50 50 50 50 50 50 50 50 50 50 50
			50 50 50 50 50 50 50 50 50 50 50 50 50 50 50 50 50 50
			50 50 50 50 50 50 50 50 50 50 50 50 50 50 50 50 50 50
			50 50 50 50 50 50 50 50 50 50 50 50 50 50 50 50 50 50
			50 50 50 50 50 50 50 50 50 50 50 50 50 50 50 50 50 50
			50 50 50 50 50 50 50 50 50 50 50 50 50 50 50 50 50 50
			50 50 50 50 50 50 50 50 50 50 50 50 50 50 50 50 50 50
			50 50 50 50 50 50 50 50 50 50 50 50 50 50 50 50 50 50
			50 50 50 50 50 50 50 50 50 50 50 50 50 50 50 50 50 50
			>;

		PS_Config_Lmt_FW_Rawdata_P = <
			1920 1920 1920 1920 1920 1920 1920 1920 1920 1920 1920 1920 1920 1920 1920 1920 1920 1920
			1920 1920 1920 1920 1920 1920 1920 1920 1920 1920 1920 1920 1920 1920 1920 1920 1920 1920
			1920 1920 1920 1920 1920 1920 1920 1920 1920 1920 1920 1920 1920 1920 1920 1920 1920 1920
			1920 1920 1920 1920 1920 1920 1920 1920 1920 1920 1920 1920 1920 1920 1920 1920 1920 1920
			1920 1920 1920 1920 1920 1920 1920 1920 1920 1920 1920 1920 1920 1920 1920 1920 1920 1920
			1920 1920 1920 1920 1920 1920 1920 1920 1920 1920 1920 1920 1920 1920 1920 1920 1920 1920
			1920 1920 1920 1920 1920 1920 1920 1920 1920 1920 1920 1920 1920 1920 1920 1920 1920 1920
			1920 1920 1920 1920 1920 1920 1920 1920 1920 1920 1920 1920 1920 1920 1920 1920 1920 1920
			1920 1920 1920 1920 1920 1920 1920 1920 1920 1920 1920 1920 1920 1920 1920 1920 1920 1920
			1920 1920 1920 1920 1920 1920 1920 1920 1920 1920 1920 1920 1920 1920 1920 1920 1920 1920
			1920 1920 1920 1920 1920 1920 1920 1920 1920 1920 1920 1920 1920 1920 1920 1920 1920 1920
			1920 1920 1920 1920 1920 1920 1920 1920 1920 1920 1920 1920 1920 1920 1920 1920 1920 1920
			1920 1920 1920 1920 1920 1920 1920 1920 1920 1920 1920 1920 1920 1920 1920 1920 1920 1920
			1920 1920 1920 1920 1920 1920 1920 1920 1920 1920 1920 1920 1920 1920 1920 1920 1920 1920
			1920 1920 1920 1920 1920 1920 1920 1920 1920 1920 1920 1920 1920 1920 1920 1920 1920 1920
			1920 1920 1920 1920 1920 1920 1920 1920 1920 1920 1920 1920 1920 1920 1920 1920 1920 1920
			1920 1920 1920 1920 1920 1920 1920 1920 1920 1920 1920 1920 1920 1920 1920 1920 1920 1920
			1920 1920 1920 1920 1920 1920 1920 1920 1920 1920 1920 1920 1920 1920 1920 1920 1920 1920
			1920 1920 1920 1920 1920 1920 1920 1920 1920 1920 1920 1920 1920 1920 1920 1920 1920 1920
			1920 1920 1920 1920 1920 1920 1920 1920 1920 1920 1920 1920 1920 1920 1920 1920 1920 1920
			1920 1920 1920 1920 1920 1920 1920 1920 1920 1920 1920 1920 1920 1920 1920 1920 1920 1920
			1920 1920 1920 1920 1920 1920 1920 1920 1920 1920 1920 1920 1920 1920 1920 1920 1920 1920
			1920 1920 1920 1920 1920 1920 1920 1920 1920 1920 1920 1920 1920 1920 1920 1920 1920 1920
			1920 1920 1920 1920 1920 1920 1920 1920 1920 1920 1920 1920 1920 1920 1920 1920 1920 1920
			1920 1920 1920 1920 1920 1920 1920 1920 1920 1920 1920 1920 1920 1920 1920 1920 1920 1920
			1920 1920 1920 1920 1920 1920 1920 1920 1920 1920 1920 1920 1920 1920 1920 1920 1920 1920
			1920 1920 1920 1920 1920 1920 1920 1920 1920 1920 1920 1920 1920 1920 1920 1920 1920 1920
			1920 1920 1920 1920 1920 1920 1920 1920 1920 1920 1920 1920 1920 1920 1920 1920 1920 1920
			1920 1920 1920 1920 1920 1920 1920 1920 1920 1920 1920 1920 1920 1920 1920 1920 1920 1920
			1920 1920 1920 1920 1920 1920 1920 1920 1920 1920 1920 1920 1920 1920 1920 1920 1920 1920
			1920 1920 1920 1920 1920 1920 1920 1920 1920 1920 1920 1920 1920 1920 1920 1920 1920 1920
			1920 1920 1920 1920 1920 1920 1920 1920 1920 1920 1920 1920 1920 1920 1920 1920 1920 1920
			>;

		PS_Config_Lmt_FW_Rawdata_N = <
			240 240 240 240 240 240 240 240 240 240 240 240 240 240 240 240 240 240
			240 240 240 240 240 240 240 240 240 240 240 240 240 240 240 240 240 240
			240 240 240 240 240 240 240 240 240 240 240 240 240 240 240 240 240 240
			240 240 240 240 240 240 240 240 240 240 240 240 240 240 240 240 240 240
			240 240 240 240 240 240 240 240 240 240 240 240 240 240 240 240 240 240
			240 240 240 240 240 240 240 240 240 240 240 240 240 240 240 240 240 240
			240 240 240 240 240 240 240 240 240 240 240 240 240 240 240 240 240 240
			240 240 240 240 240 240 240 240 240 240 240 240 240 240 240 240 240 240
			240 240 240 240 240 240 240 240 240 240 240 240 240 240 240 240 240 240
			240 240 240 240 240 240 240 240 240 240 240 240 240 240 240 240 240 240
			240 240 240 240 240 240 240 240 240 240 240 240 240 240 240 240 240 240
			240 240 240 240 240 240 240 240 240 240 240 240 240 240 240 240 240 240
			240 240 240 240 240 240 240 240 240 240 240 240 240 240 240 240 240 240
			240 240 240 240 240 240 240 240 240 240 240 240 240 240 240 240 240 240
			240 240 240 240 240 240 240 240 240 240 240 240 240 240 240 240 240 240
			240 240 240 240 240 240 240 240 240 240 240 240 240 240 240 240 240 240
			240 240 240 240 240 240 240 240 240 240 240 240 240 240 240 240 240 240
			240 240 240 240 240 240 240 240 240 240 240 240 240 240 240 240 240 240
			240 240 240 240 240 240 240 240 240 240 240 240 240 240 240 240 240 240
			240 240 240 240 240 240 240 240 240 240 240 240 240 240 240 240 240 240
			240 240 240 240 240 240 240 240 240 240 240 240 240 240 240 240 240 240
			240 240 240 240 240 240 240 240 240 240 240 240 240 240 240 240 240 240
			240 240 240 240 240 240 240 240 240 240 240 240 240 240 240 240 240 240
			240 240 240 240 240 240 240 240 240 240 240 240 240 240 240 240 240 240
			240 240 240 240 240 240 240 240 240 240 240 240 240 240 240 240 240 240
			240 240 240 240 240 240 240 240 240 240 240 240 240 240 240 240 240 240
			240 240 240 240 240 240 240 240 240 240 240 240 240 240 240 240 240 240
			240 240 240 240 240 240 240 240 240 240 240 240 240 240 240 240 240 240
			240 240 240 240 240 240 240 240 240 240 240 240 240 240 240 240 240 240
			240 240 240 240 240 240 240 240 240 240 240 240 240 240 240 240 240 240
			240 240 240 240 240 240 240 240 240 240 240 240 240 240 240 240 240 240
			240 240 240 240 240 240 240 240 240 240 240 240 240 240 240 240 240 240
			>;

		PS_Config_Lmt_FW_CC_P = <
			314 314 314 314 314 314 314 314 314 314 314 314 314 314 314 314 314 314
			314 314 314 314 314 314 314 314 314 314 314 314 314 314 314 314 314 314
			314 314 314 314 314 314 314 314 314 314 314 314 314 314 314 314 314 314
			314 314 314 314 314 314 314 314 314 314 314 314 314 314 314 314 314 314
			314 314 314 314 314 314 314 314 314 314 314 314 314 314 314 314 314 314
			314 314 314 314 314 314 314 314 314 314 314 314 314 314 314 314 314 314
			314 314 314 314 314 314 314 314 314 314 314 314 314 314 314 314 314 314
			314 314 314 314 314 314 314 314 314 314 314 314 314 314 314 314 314 314
			314 314 314 314 314 314 314 314 314 314 314 314 314 314 314 314 314 314
			314 314 314 314 314 314 314 314 314 314 314 314 314 314 314 314 314 314
			314 314 314 314 314 314 314 314 314 314 314 314 314 314 314 314 314 314
			314 314 314 314 314 314 314 314 314 314 314 314 314 314 314 314 314 314
			314 314 314 314 314 314 314 314 314 314 314 314 314 314 314 314 314 314
			314 314 314 314 314 314 314 314 314 314 314 314 314 314 314 314 314 314
			314 314 314 314 314 314 314 314 314 314 314 314 314 314 314 314 314 314
			314 314 314 314 314 314 314 314 314 314 314 314 314 314 314 314 314 314
			314 314 314 314 314 314 314 314 314 314 314 314 314 314 314 314 314 314
			314 314 314 314 314 314 314 314 314 314 314 314 314 314 314 314 314 314
			314 314 314 314 314 314 314 314 314 314 314 314 314 314 314 314 314 314
			314 314 314 314 314 314 314 314 314 314 314 314 314 314 314 314 314 314
			314 314 314 314 314 314 314 314 314 314 314 314 314 314 314 314 314 314
			314 314 314 314 314 314 314 314 314 314 314 314 314 314 314 314 314 314
			314 314 314 314 314 314 314 314 314 314 314 314 314 314 314 314 314 314
			314 314 314 314 314 314 314 314 314 314 314 314 314 314 314 314 314 314
			314 314 314 314 314 314 314 314 314 314 314 314 314 314 314 314 314 314
			314 314 314 314 314 314 314 314 314 314 314 314 314 314 314 314 314 314
			314 314 314 314 314 314 314 314 314 314 314 314 314 314 314 314 314 314
			314 314 314 314 314 314 314 314 314 314 314 314 314 314 314 314 314 314
			314 314 314 314 314 314 314 314 314 314 314 314 314 314 314 314 314 314
			314 314 314 314 314 314 314 314 314 314 314 314 314 314 314 314 314 314
			314 314 314 314 314 314 314 314 314 314 314 314 314 314 314 314 314 314
			314 314 314 314 314 314 314 314 314 314 314 314 314 314 314 314 314 314
			>;

		PS_Config_Lmt_FW_CC_N = <
			30 30 30 30 30 30 30 30 30 30 30 30 30 30 30 30 30 30
			30 30 30 30 30 30 30 30 30 30 30 30 30 30 30 30 30 30
			30 30 30 30 30 30 30 30 30 30 30 30 30 30 30 30 30 30
			30 30 30 30 30 30 30 30 30 30 30 30 30 30 30 30 30 30
			30 30 30 30 30 30 30 30 30 30 30 30 30 30 30 30 30 30
			30 30 30 30 30 30 30 30 30 30 30 30 30 30 30 30 30 30
			30 30 30 30 30 30 30 30 30 30 30 30 30 30 30 30 30 30
			30 30 30 30 30 30 30 30 30 30 30 30 30 30 30 30 30 30
			30 30 30 30 30 30 30 30 30 30 30 30 30 30 30 30 30 30
			30 30 30 30 30 30 30 30 30 30 30 30 30 30 30 30 30 30
			30 30 30 30 30 30 30 30 30 30 30 30 30 30 30 30 30 30
			30 30 30 30 30 30 30 30 30 30 30 30 30 30 30 30 30 30
			30 30 30 30 30 30 30 30 30 30 30 30 30 30 30 30 30 30
			30 30 30 30 30 30 30 30 30 30 30 30 30 30 30 30 30 30
			30 30 30 30 30 30 30 30 30 30 30 30 30 30 30 30 30 30
			30 30 30 30 30 30 30 30 30 30 30 30 30 30 30 30 30 30
			30 30 30 30 30 30 30 30 30 30 30 30 30 30 30 30 30 30
			30 30 30 30 30 30 30 30 30 30 30 30 30 30 30 30 30 30
			30 30 30 30 30 30 30 30 30 30 30 30 30 30 30 30 30 30
			30 30 30 30 30 30 30 30 30 30 30 30 30 30 30 30 30 30
			30 30 30 30 30 30 30 30 30 30 30 30 30 30 30 30 30 30
			30 30 30 30 30 30 30 30 30 30 30 30 30 30 30 30 30 30
			30 30 30 30 30 30 30 30 30 30 30 30 30 30 30 30 30 30
			30 30 30 30 30 30 30 30 30 30 30 30 30 30 30 30 30 30
			30 30 30 30 30 30 30 30 30 30 30 30 30 30 30 30 30 30
			30 30 30 30 30 30 30 30 30 30 30 30 30 30 30 30 30 30
			30 30 30 30 30 30 30 30 30 30 30 30 30 30 30 30 30 30
			30 30 30 30 30 30 30 30 30 30 30 30 30 30 30 30 30 30
			30 30 30 30 30 30 30 30 30 30 30 30 30 30 30 30 30 30
			30 30 30 30 30 30 30 30 30 30 30 30 30 30 30 30 30 30
			30 30 30 30 30 30 30 30 30 30 30 30 30 30 30 30 30 30
			30 30 30 30 30 30 30 30 30 30 30 30 30 30 30 30 30 30
			>;

		PS_Config_Lmt_FW_Diff_P = <
			75 75 75 75 75 75 75 75 75 75 75 75 75 75 75 75 75 75
			75 75 75 75 75 75 75 75 75 75 75 75 75 75 75 75 75 75
			75 75 75 75 75 75 75 75 75 75 75 75 75 75 75 75 75 75
			75 75 75 75 75 75 75 75 75 75 75 75 75 75 75 75 75 75
			75 75 75 75 75 75 75 75 75 75 75 75 75 75 75 75 75 75
			75 75 75 75 75 75 75 75 75 75 75 75 75 75 75 75 75 75
			75 75 75 75 75 75 75 75 75 75 75 75 75 75 75 75 75 75
			75 75 75 75 75 75 75 75 75 75 75 75 75 75 75 75 75 75
			75 75 75 75 75 75 75 75 75 75 75 75 75 75 75 75 75 75
			75 75 75 75 75 75 75 75 75 75 75 75 75 75 75 75 75 75
			75 75 75 75 75 75 75 75 75 75 75 75 75 75 75 75 75 75
			75 75 75 75 75 75 75 75 75 75 75 75 75 75 75 75 75 75
			75 75 75 75 75 75 75 75 75 75 75 75 75 75 75 75 75 75
			75 75 75 75 75 75 75 75 75 75 75 75 75 75 75 75 75 75
			75 75 75 75 75 75 75 75 75 75 75 75 75 75 75 75 75 75
			75 75 75 75 75 75 75 75 75 75 75 75 75 75 75 75 75 75
			75 75 75 75 75 75 75 75 75 75 75 75 75 75 75 75 75 75
			75 75 75 75 75 75 75 75 75 75 75 75 75 75 75 75 75 75
			75 75 75 75 75 75 75 75 75 75 75 75 75 75 75 75 75 75
			75 75 75 75 75 75 75 75 75 75 75 75 75 75 75 75 75 75
			75 75 75 75 75 75 75 75 75 75 75 75 75 75 75 75 75 75
			75 75 75 75 75 75 75 75 75 75 75 75 75 75 75 75 75 75
			75 75 75 75 75 75 75 75 75 75 75 75 75 75 75 75 75 75
			75 75 75 75 75 75 75 75 75 75 75 75 75 75 75 75 75 75
			75 75 75 75 75 75 75 75 75 75 75 75 75 75 75 75 75 75
			75 75 75 75 75 75 75 75 75 75 75 75 75 75 75 75 75 75
			75 75 75 75 75 75 75 75 75 75 75 75 75 75 75 75 75 75
			75 75 75 75 75 75 75 75 75 75 75 75 75 75 75 75 75 75
			75 75 75 75 75 75 75 75 75 75 75 75 75 75 75 75 75 75
			75 75 75 75 75 75 75 75 75 75 75 75 75 75 75 75 75 75
			75 75 75 75 75 75 75 75 75 75 75 75 75 75 75 75 75 75
			75 75 75 75 75 75 75 75 75 75 75 75 75 75 75 75 75 75
			>;

		PS_Config_Lmt_FW_Diff_N = <
			(-75) (-75) (-75) (-75) (-75) (-75) (-75) (-75) (-75) (-75) (-75) (-75) (-75) (-75) (-75) (-75) (-75) (-75)
			(-75) (-75) (-75) (-75) (-75) (-75) (-75) (-75) (-75) (-75) (-75) (-75) (-75) (-75) (-75) (-75) (-75) (-75)
			(-75) (-75) (-75) (-75) (-75) (-75) (-75) (-75) (-75) (-75) (-75) (-75) (-75) (-75) (-75) (-75) (-75) (-75)
			(-75) (-75) (-75) (-75) (-75) (-75) (-75) (-75) (-75) (-75) (-75) (-75) (-75) (-75) (-75) (-75) (-75) (-75)
			(-75) (-75) (-75) (-75) (-75) (-75) (-75) (-75) (-75) (-75) (-75) (-75) (-75) (-75) (-75) (-75) (-75) (-75)
			(-75) (-75) (-75) (-75) (-75) (-75) (-75) (-75) (-75) (-75) (-75) (-75) (-75) (-75) (-75) (-75) (-75) (-75)
			(-75) (-75) (-75) (-75) (-75) (-75) (-75) (-75) (-75) (-75) (-75) (-75) (-75) (-75) (-75) (-75) (-75) (-75)
			(-75) (-75) (-75) (-75) (-75) (-75) (-75) (-75) (-75) (-75) (-75) (-75) (-75) (-75) (-75) (-75) (-75) (-75)
			(-75) (-75) (-75) (-75) (-75) (-75) (-75) (-75) (-75) (-75) (-75) (-75) (-75) (-75) (-75) (-75) (-75) (-75)
			(-75) (-75) (-75) (-75) (-75) (-75) (-75) (-75) (-75) (-75) (-75) (-75) (-75) (-75) (-75) (-75) (-75) (-75)
			(-75) (-75) (-75) (-75) (-75) (-75) (-75) (-75) (-75) (-75) (-75) (-75) (-75) (-75) (-75) (-75) (-75) (-75)
			(-75) (-75) (-75) (-75) (-75) (-75) (-75) (-75) (-75) (-75) (-75) (-75) (-75) (-75) (-75) (-75) (-75) (-75)
			(-75) (-75) (-75) (-75) (-75) (-75) (-75) (-75) (-75) (-75) (-75) (-75) (-75) (-75) (-75) (-75) (-75) (-75)
			(-75) (-75) (-75) (-75) (-75) (-75) (-75) (-75) (-75) (-75) (-75) (-75) (-75) (-75) (-75) (-75) (-75) (-75)
			(-75) (-75) (-75) (-75) (-75) (-75) (-75) (-75) (-75) (-75) (-75) (-75) (-75) (-75) (-75) (-75) (-75) (-75)
			(-75) (-75) (-75) (-75) (-75) (-75) (-75) (-75) (-75) (-75) (-75) (-75) (-75) (-75) (-75) (-75) (-75) (-75)
			(-75) (-75) (-75) (-75) (-75) (-75) (-75) (-75) (-75) (-75) (-75) (-75) (-75) (-75) (-75) (-75) (-75) (-75)
			(-75) (-75) (-75) (-75) (-75) (-75) (-75) (-75) (-75) (-75) (-75) (-75) (-75) (-75) (-75) (-75) (-75) (-75)
			(-75) (-75) (-75) (-75) (-75) (-75) (-75) (-75) (-75) (-75) (-75) (-75) (-75) (-75) (-75) (-75) (-75) (-75)
			(-75) (-75) (-75) (-75) (-75) (-75) (-75) (-75) (-75) (-75) (-75) (-75) (-75) (-75) (-75) (-75) (-75) (-75)
			(-75) (-75) (-75) (-75) (-75) (-75) (-75) (-75) (-75) (-75) (-75) (-75) (-75) (-75) (-75) (-75) (-75) (-75)
			(-75) (-75) (-75) (-75) (-75) (-75) (-75) (-75) (-75) (-75) (-75) (-75) (-75) (-75) (-75) (-75) (-75) (-75)
			(-75) (-75) (-75) (-75) (-75) (-75) (-75) (-75) (-75) (-75) (-75) (-75) (-75) (-75) (-75) (-75) (-75) (-75)
			(-75) (-75) (-75) (-75) (-75) (-75) (-75) (-75) (-75) (-75) (-75) (-75) (-75) (-75) (-75) (-75) (-75) (-75)
			(-75) (-75) (-75) (-75) (-75) (-75) (-75) (-75) (-75) (-75) (-75) (-75) (-75) (-75) (-75) (-75) (-75) (-75)
			(-75) (-75) (-75) (-75) (-75) (-75) (-75) (-75) (-75) (-75) (-75) (-75) (-75) (-75) (-75) (-75) (-75) (-75)
			(-75) (-75) (-75) (-75) (-75) (-75) (-75) (-75) (-75) (-75) (-75) (-75) (-75) (-75) (-75) (-75) (-75) (-75)
			(-75) (-75) (-75) (-75) (-75) (-75) (-75) (-75) (-75) (-75) (-75) (-75) (-75) (-75) (-75) (-75) (-75) (-75)
			(-75) (-75) (-75) (-75) (-75) (-75) (-75) (-75) (-75) (-75) (-75) (-75) (-75) (-75) (-75) (-75) (-75) (-75)
			(-75) (-75) (-75) (-75) (-75) (-75) (-75) (-75) (-75) (-75) (-75) (-75) (-75) (-75) (-75) (-75) (-75) (-75)
			(-75) (-75) (-75) (-75) (-75) (-75) (-75) (-75) (-75) (-75) (-75) (-75) (-75) (-75) (-75) (-75) (-75) (-75)
			(-75) (-75) (-75) (-75) (-75) (-75) (-75) (-75) (-75) (-75) (-75) (-75) (-75) (-75) (-75) (-75) (-75) (-75)
			>;

		PS_Config_Diff_Test_Frame = <50>;

		PS_Config_Lmt_LPWG_Rawdata_P = <
			1920 1920 1920 1920 1920 1920 1920 1920 1920 1920 1920 1920 1920 1920 1920 1920 1920 1920
			1920 1920 1920 1920 1920 1920 1920 1920 1920 1920 1920 1920 1920 1920 1920 1920 1920 1920
			1920 1920 1920 1920 1920 1920 1920 1920 1920 1920 1920 1920 1920 1920 1920 1920 1920 1920
			1920 1920 1920 1920 1920 1920 1920 1920 1920 1920 1920 1920 1920 1920 1920 1920 1920 1920
			1920 1920 1920 1920 1920 1920 1920 1920 1920 1920 1920 1920 1920 1920 1920 1920 1920 1920
			1920 1920 1920 1920 1920 1920 1920 1920 1920 1920 1920 1920 1920 1920 1920 1920 1920 1920
			1920 1920 1920 1920 1920 1920 1920 1920 1920 1920 1920 1920 1920 1920 1920 1920 1920 1920
			1920 1920 1920 1920 1920 1920 1920 1920 1920 1920 1920 1920 1920 1920 1920 1920 1920 1920
			1920 1920 1920 1920 1920 1920 1920 1920 1920 1920 1920 1920 1920 1920 1920 1920 1920 1920
			1920 1920 1920 1920 1920 1920 1920 1920 1920 1920 1920 1920 1920 1920 1920 1920 1920 1920
			1920 1920 1920 1920 1920 1920 1920 1920 1920 1920 1920 1920 1920 1920 1920 1920 1920 1920
			1920 1920 1920 1920 1920 1920 1920 1920 1920 1920 1920 1920 1920 1920 1920 1920 1920 1920
			1920 1920 1920 1920 1920 1920 1920 1920 1920 1920 1920 1920 1920 1920 1920 1920 1920 1920
			1920 1920 1920 1920 1920 1920 1920 1920 1920 1920 1920 1920 1920 1920 1920 1920 1920 1920
			1920 1920 1920 1920 1920 1920 1920 1920 1920 1920 1920 1920 1920 1920 1920 1920 1920 1920
			1920 1920 1920 1920 1920 1920 1920 1920 1920 1920 1920 1920 1920 1920 1920 1920 1920 1920
			1920 1920 1920 1920 1920 1920 1920 1920 1920 1920 1920 1920 1920 1920 1920 1920 1920 1920
			1920 1920 1920 1920 1920 1920 1920 1920 1920 1920 1920 1920 1920 1920 1920 1920 1920 1920
			1920 1920 1920 1920 1920 1920 1920 1920 1920 1920 1920 1920 1920 1920 1920 1920 1920 1920
			1920 1920 1920 1920 1920 1920 1920 1920 1920 1920 1920 1920 1920 1920 1920 1920 1920 1920
			1920 1920 1920 1920 1920 1920 1920 1920 1920 1920 1920 1920 1920 1920 1920 1920 1920 1920
			1920 1920 1920 1920 1920 1920 1920 1920 1920 1920 1920 1920 1920 1920 1920 1920 1920 1920
			1920 1920 1920 1920 1920 1920 1920 1920 1920 1920 1920 1920 1920 1920 1920 1920 1920 1920
			1920 1920 1920 1920 1920 1920 1920 1920 1920 1920 1920 1920 1920 1920 1920 1920 1920 1920
			1920 1920 1920 1920 1920 1920 1920 1920 1920 1920 1920 1920 1920 1920 1920 1920 1920 1920
			1920 1920 1920 1920 1920 1920 1920 1920 1920 1920 1920 1920 1920 1920 1920 1920 1920 1920
			1920 1920 1920 1920 1920 1920 1920 1920 1920 1920 1920 1920 1920 1920 1920 1920 1920 1920
			1920 1920 1920 1920 1920 1920 1920 1920 1920 1920 1920 1920 1920 1920 1920 1920 1920 1920
			1920 1920 1920 1920 1920 1920 1920 1920 1920 1920 1920 1920 1920 1920 1920 1920 1920 1920
			1920 1920 1920 1920 1920 1920 1920 1920 1920 1920 1920 1920 1920 1920 1920 1920 1920 1920
			1920 1920 1920 1920 1920 1920 1920 1920 1920 1920 1920 1920 1920 1920 1920 1920 1920 1920
			1920 1920 1920 1920 1920 1920 1920 1920 1920 1920 1920 1920 1920 1920 1920 1920 1920 1920
			>;

		PS_Config_Lmt_LPWG_Rawdata_N = <
			240 240 240 240 240 240 240 240 240 240 240 240 240 240 240 240 240 240
			240 240 240 240 240 240 240 240 240 240 240 240 240 240 240 240 240 240
			240 240 240 240 240 240 240 240 240 240 240 240 240 240 240 240 240 240
			240 240 240 240 240 240 240 240 240 240 240 240 240 240 240 240 240 240
			240 240 240 240 240 240 240 240 240 240 240 240 240 240 240 240 240 240
			240 240 240 240 240 240 240 240 240 240 240 240 240 240 240 240 240 240
			240 240 240 240 240 240 240 240 240 240 240 240 240 240 240 240 240 240
			240 240 240 240 240 240 240 240 240 240 240 240 240 240 240 240 240 240
			240 240 240 240 240 240 240 240 240 240 240 240 240 240 240 240 240 240
			240 240 240 240 240 240 240 240 240 240 240 240 240 240 240 240 240 240
			240 240 240 240 240 240 240 240 240 240 240 240 240 240 240 240 240 240
			240 240 240 240 240 240 240 240 240 240 240 240 240 240 240 240 240 240
			240 240 240 240 240 240 240 240 240 240 240 240 240 240 240 240 240 240
			240 240 240 240 240 240 240 240 240 240 240 240 240 240 240 240 240 240
			240 240 240 240 240 240 240 240 240 240 240 240 240 240 240 240 240 240
			240 240 240 240 240 240 240 240 240 240 240 240 240 240 240 240 240 240
			240 240 240 240 240 240 240 240 240 240 240 240 240 240 240 240 240 240
			240 240 240 240 240 240 240 240 240 240 240 240 240 240 240 240 240 240
			240 240 240 240 240 240 240 240 240 240 240 240 240 240 240 240 240 240
			240 240 240 240 240 240 240 240 240 240 240 240 240 240 240 240 240 240
			240 240 240 240 240 240 240 240 240 240 240 240 240 240 240 240 240 240
			240 240 240 240 240 240 240 240 240 240 240 240 240 240 240 240 240 240
			240 240 240 240 240 240 240 240 240 240 240 240 240 240 240 240 240 240
			240 240 240 240 240 240 240 240 240 240 240 240 240 240 240 240 240 240
			240 240 240 240 240 240 240 240 240 240 240 240 240 240 240 240 240 240
			240 240 240 240 240 240 240 240 240 240 240 240 240 240 240 240 240 240
			240 240 240 240 240 240 240 240 240 240 240 240 240 240 240 240 240 240
			240 240 240 240 240 240 240 240 240 240 240 240 240 240 240 240 240 240
			240 240 240 240 240 240 240 240 240 240 240 240 240 240 240 240 240 240
			240 240 240 240 240 240 240 240 240 240 240 240 240 240 240 240 240 240
			240 240 240 240 240 240 240 240 240 240 240 240 240 240 240 240 240 240
			240 240 240 240 240 240 240 240 240 240 240 240 240 240 240 240 240 240
			>;

		PS_Config_Lmt_LPWG_Diff_P = <
			90 90 90 90 90 90 90 90 90 90 90 90 90 90 90 90 90 90
			90 90 90 90 90 90 90 90 90 90 90 90 90 90 90 90 90 90
			90 90 90 90 90 90 90 90 90 90 90 90 90 90 90 90 90 90
			90 90 90 90 90 90 90 90 90 90 90 90 90 90 90 90 90 90
			90 90 90 90 90 90 90 90 90 90 90 90 90 90 90 90 90 90
			90 90 90 90 90 90 90 90 90 90 90 90 90 90 90 90 90 90
			90 90 90 90 90 90 90 90 90 90 90 90 90 90 90 90 90 90
			90 90 90 90 90 90 90 90 90 90 90 90 90 90 90 90 90 90
			90 90 90 90 90 90 90 90 90 90 90 90 90 90 90 90 90 90
			90 90 90 90 90 90 90 90 90 90 90 90 90 90 90 90 90 90
			90 90 90 90 90 90 90 90 90 90 90 90 90 90 90 90 90 90
			90 90 90 90 90 90 90 90 90 90 90 90 90 90 90 90 90 90
			90 90 90 90 90 90 90 90 90 90 90 90 90 90 90 90 90 90
			90 90 90 90 90 90 90 90 90 90 90 90 90 90 90 90 90 90
			90 90 90 90 90 90 90 90 90 90 90 90 90 90 90 90 90 90
			90 90 90 90 90 90 90 90 90 90 90 90 90 90 90 90 90 90
			90 90 90 90 90 90 90 90 90 90 90 90 90 90 90 90 90 90
			90 90 90 90 90 90 90 90 90 90 90 90 90 90 90 90 90 90
			90 90 90 90 90 90 90 90 90 90 90 90 90 90 90 90 90 90
			90 90 90 90 90 90 90 90 90 90 90 90 90 90 90 90 90 90
			90 90 90 90 90 90 90 90 90 90 90 90 90 90 90 90 90 90
			90 90 90 90 90 90 90 90 90 90 90 90 90 90 90 90 90 90
			90 90 90 90 90 90 90 90 90 90 90 90 90 90 90 90 90 90
			90 90 90 90 90 90 90 90 90 90 90 90 90 90 90 90 90 90
			90 90 90 90 90 90 90 90 90 90 90 90 90 90 90 90 90 90
			90 90 90 90 90 90 90 90 90 90 90 90 90 90 90 90 90 90
			90 90 90 90 90 90 90 90 90 90 90 90 90 90 90 90 90 90
			90 90 90 90 90 90 90 90 90 90 90 90 90 90 90 90 90 90
			90 90 90 90 90 90 90 90 90 90 90 90 90 90 90 90 90 90
			90 90 90 90 90 90 90 90 90 90 90 90 90 90 90 90 90 90
			90 90 90 90 90 90 90 90 90 90 90 90 90 90 90 90 90 90
			90 90 90 90 90 90 90 90 90 90 90 90 90 90 90 90 90 90
			>;

		PS_Config_Lmt_LPWG_Diff_N = <
			(-90) (-90) (-90) (-90) (-90) (-90) (-90) (-90) (-90) (-90) (-90) (-90) (-90) (-90) (-90) (-90) (-90) (-90)
			(-90) (-90) (-90) (-90) (-90) (-90) (-90) (-90) (-90) (-90) (-90) (-90) (-90) (-90) (-90) (-90) (-90) (-90)
			(-90) (-90) (-90) (-90) (-90) (-90) (-90) (-90) (-90) (-90) (-90) (-90) (-90) (-90) (-90) (-90) (-90) (-90)
			(-90) (-90) (-90) (-90) (-90) (-90) (-90) (-90) (-90) (-90) (-90) (-90) (-90) (-90) (-90) (-90) (-90) (-90)
			(-90) (-90) (-90) (-90) (-90) (-90) (-90) (-90) (-90) (-90) (-90) (-90) (-90) (-90) (-90) (-90) (-90) (-90)
			(-90) (-90) (-90) (-90) (-90) (-90) (-90) (-90) (-90) (-90) (-90) (-90) (-90) (-90) (-90) (-90) (-90) (-90)
			(-90) (-90) (-90) (-90) (-90) (-90) (-90) (-90) (-90) (-90) (-90) (-90) (-90) (-90) (-90) (-90) (-90) (-90)
			(-90) (-90) (-90) (-90) (-90) (-90) (-90) (-90) (-90) (-90) (-90) (-90) (-90) (-90) (-90) (-90) (-90) (-90)
			(-90) (-90) (-90) (-90) (-90) (-90) (-90) (-90) (-90) (-90) (-90) (-90) (-90) (-90) (-90) (-90) (-90) (-90)
			(-90) (-90) (-90) (-90) (-90) (-90) (-90) (-90) (-90) (-90) (-90) (-90) (-90) (-90) (-90) (-90) (-90) (-90)
			(-90) (-90) (-90) (-90) (-90) (-90) (-90) (-90) (-90) (-90) (-90) (-90) (-90) (-90) (-90) (-90) (-90) (-90)
			(-90) (-90) (-90) (-90) (-90) (-90) (-90) (-90) (-90) (-90) (-90) (-90) (-90) (-90) (-90) (-90) (-90) (-90)
			(-90) (-90) (-90) (-90) (-90) (-90) (-90) (-90) (-90) (-90) (-90) (-90) (-90) (-90) (-90) (-90) (-90) (-90)
			(-90) (-90) (-90) (-90) (-90) (-90) (-90) (-90) (-90) (-90) (-90) (-90) (-90) (-90) (-90) (-90) (-90) (-90)
			(-90) (-90) (-90) (-90) (-90) (-90) (-90) (-90) (-90) (-90) (-90) (-90) (-90) (-90) (-90) (-90) (-90) (-90)
			(-90) (-90) (-90) (-90) (-90) (-90) (-90) (-90) (-90) (-90) (-90) (-90) (-90) (-90) (-90) (-90) (-90) (-90)
			(-90) (-90) (-90) (-90) (-90) (-90) (-90) (-90) (-90) (-90) (-90) (-90) (-90) (-90) (-90) (-90) (-90) (-90)
			(-90) (-90) (-90) (-90) (-90) (-90) (-90) (-90) (-90) (-90) (-90) (-90) (-90) (-90) (-90) (-90) (-90) (-90)
			(-90) (-90) (-90) (-90) (-90) (-90) (-90) (-90) (-90) (-90) (-90) (-90) (-90) (-90) (-90) (-90) (-90) (-90)
			(-90) (-90) (-90) (-90) (-90) (-90) (-90) (-90) (-90) (-90) (-90) (-90) (-90) (-90) (-90) (-90) (-90) (-90)
			(-90) (-90) (-90) (-90) (-90) (-90) (-90) (-90) (-90) (-90) (-90) (-90) (-90) (-90) (-90) (-90) (-90) (-90)
			(-90) (-90) (-90) (-90) (-90) (-90) (-90) (-90) (-90) (-90) (-90) (-90) (-90) (-90) (-90) (-90) (-90) (-90)
			(-90) (-90) (-90) (-90) (-90) (-90) (-90) (-90) (-90) (-90) (-90) (-90) (-90) (-90) (-90) (-90) (-90) (-90)
			(-90) (-90) (-90) (-90) (-90) (-90) (-90) (-90) (-90) (-90) (-90) (-90) (-90) (-90) (-90) (-90) (-90) (-90)
			(-90) (-90) (-90) (-90) (-90) (-90) (-90) (-90) (-90) (-90) (-90) (-90) (-90) (-90) (-90) (-90) (-90) (-90)
			(-90) (-90) (-90) (-90) (-90) (-90) (-90) (-90) (-90) (-90) (-90) (-90) (-90) (-90) (-90) (-90) (-90) (-90)
			(-90) (-90) (-90) (-90) (-90) (-90) (-90) (-90) (-90) (-90) (-90) (-90) (-90) (-90) (-90) (-90) (-90) (-90)
			(-90) (-90) (-90) (-90) (-90) (-90) (-90) (-90) (-90) (-90) (-90) (-90) (-90) (-90) (-90) (-90) (-90) (-90)
			(-90) (-90) (-90) (-90) (-90) (-90) (-90) (-90) (-90) (-90) (-90) (-90) (-90) (-90) (-90) (-90) (-90) (-90)
			(-90) (-90) (-90) (-90) (-90) (-90) (-90) (-90) (-90) (-90) (-90) (-90) (-90) (-90) (-90) (-90) (-90) (-90)
			(-90) (-90) (-90) (-90) (-90) (-90) (-90) (-90) (-90) (-90) (-90) (-90) (-90) (-90) (-90) (-90) (-90) (-90)
			(-90) (-90) (-90) (-90) (-90) (-90) (-90) (-90) (-90) (-90) (-90) (-90) (-90) (-90) (-90) (-90) (-90) (-90)
			>;
	}; /* novatek-mp-criteria-hlt */
    };
};
//#endif
/* TOUCH end */

&i2c0 {
      lcm_bias@3e{
               compatible = "LCD_BIAS_SM5109","LCD_BIAS_OCP2130";
               reg = <0x3e>;
               status = "okay";
       };
};
&i2c2 {
	clock-frequency = <400000>;

	mtk-usb@60 {
		compatible = "mediatek,mtk-usb";
		reg = <0x60>;
		status = "okay";
	};
};

//#ifdef ODM_WT_EDIT
//Yuexiu.Wu@ODM_WT.WCN.NFC, 2019/10/05, Add for NFC bringup
//Yuexiu.Wu@ODM_WT.WCN.NFC.Basic.1941873,2019/12/14,delete for use MTK driver
/*&i2c3{
     pn544:nfc@28 {
         compatible = "nxp,pn544";
         reg = <0x28>;
         pn544-irq = <&pio 6 0x0>;
         pn544-ven = <&pio 54 0x0>;
         pn544-fw-dwnld = <&pio 19 0x0>;
         pn544-clkreq = <&pio 11 0x0>;
         status = "okay";
    };
};*/
 //#endif


/* accdet start */
&accdet {
	/* accdet micbias voltage: 0x07,2.7v;0x05,2.5v;0x02,1.9v */
	/* #ifdef ODM_WT_EDIT */
	/* Zengchao.Duan@ODM_WT.mm.audiodriver.Machine, 2019/10/28, Add for setting micbias voltage to 2.7v */
	accdet-mic-vol = <7>;
	/* #endif */
	headset-mode-setting = <0x500 0x500 1 0x1f0 0x800 0x800 0x20 0x44>;
	accdet-plugout-debounce = <1>;
	/*1:ACC mode, 2:low cost without in bias, 6:low cost with in bias*/
	accdet-mic-mode = <1>;
	/* eint_level_trigger: 8,LEVEL_LOW(DEF) ;4,LV_HIGH;others,LV_LOW */
	headset-eint-level-pol = <8>;
	/*0--MD_MAX--UP_MAX--DW_MAX*/
	headset-three-key-threshold = <0 80 220 400>;
	headset-three-key-threshold-CDD = <0 121 192 600>;
	/*0--MD_MAX--VOICE_MAX--UP_MAX--DW_MAX*/
	headset-four-key-threshold = <0 58 121 192 400>;
	status = "okay";
};
/* accdet end */

&mt6370_pmu {
	mt6370,intr_gpio_num = <20>; /* direct defined GPIO num */
	mt6370,intr_gpio = <&pio 20 0x0>;
};
&mt6370_typec {
	mt6370pd,intr_gpio_num = <41>; /* direct defined GPIO num */
	mt6370pd,intr_gpio = <&pio 41 0x0>;
};

/* CONSYS GPIO standardization */
&pio {
	consys_pins_default: consys_default {
	};
	gpslna_pins_init: gpslna@0 {
            //#ifdef ODM_WT_EDIT
            //Yuexiu.Wu@ODM_WT.WCN.NFC.Basic.1941873,2019/10/08,assign new GPS LNA gpio
            pins_cmd_dat {
                pinmux = <PINMUX_GPIO53__FUNC_GPIO53>;
                //#ifndef VENDOR_EDIT
                //Wenjie.Liu@PSW.CN.GPS.Hardware.Power.1202743, 2017/12/29,
                //modify for: [GPS_LNA gpio's output direction is out]
                /*
                slew-rate = <0>;
                */
                slew-rate = <1>;
                //#endif /* VENDOR_EDIT */
                bias-disable;
                output-low;
            };
            //#endif /* ODM_WT_EDIT */
	};
	gpslna_pins_oh: gpslna@1 {
            //#ifdef ODM_WT_EDIT
            //Yuexiu.Wu@ODM_WT.WCN.NFC.Basic.1941873,2019/10/08,assign new GPS LNA gpio
            pins_cmd_dat {
                pinmux = <PINMUX_GPIO53__FUNC_GPIO53>;
                slew-rate = <1>;
                output-high;
            };
            //#endif /* ODM_WT_EDIT */
	};
	gpslna_pins_ol: gpslna@2 {
            //#ifdef ODM_WT_EDIT
            //Yuexiu.Wu@ODM_WT.WCN.NFC.Basic.1941873,2019/10/08,assign new GPS LNA gpio
            pins_cmd_dat {
                pinmux = <PINMUX_GPIO53__FUNC_GPIO53>;
                slew-rate = <1>;
                output-low;
            };
            //#endif /* ODM_WT_EDIT */
	};
};
&consys {
	pinctrl-names = "default", "gps_lna_state_init",
		"gps_lna_state_oh", "gps_lna_state_ol";
	pinctrl-0 = <&consys_pins_default>;
	pinctrl-1 = <&gpslna_pins_init>;
	pinctrl-2 = <&gpslna_pins_oh>;
	pinctrl-3 = <&gpslna_pins_ol>;
	status = "okay";
};
/* CONSYS end */

/* IRTX GPIO Start */
&irtx_pwm {
	pinctrl-names = "irtx_gpio_led_default", "irtx_gpio_led_set";
	pinctrl-0 = <&irtx_gpio_led_default>;
	pinctrl-1 = <&irtx_gpio_led_set>;
	status = "okay";
};
&pio {
	/* IRTX GPIO Settings -Start */
	/* default: GPIO0, output, high */
	irtx_gpio_led_default:irtx_gpio_led_def@gpio12 {
		pins_cmd_dat {
			pinmux = <PINMUX_GPIO12__FUNC_GPIO12>;
			slew-rate = <1>;
			bias-disable;
			output-low;
			input-schmitt-enable = <0>;
		};
	};

	irtx_gpio_led_set:irtx_gpio_led_set@gpio12 {
		pins_cmd_dat {
			pinmux = <PINMUX_GPIO12__FUNC_PWM0>;
			slew-rate = <1>;
			output-high;
		};
	};
}; /* IRTX GPIO Settings -End */

/* DISPSYS GPIO standardization */
&pio {
	mtkfb_pins_lcm_rst_out1_gpio: lcm_rst_out1_gpio {
		pins_cmd_dat {
			pinmux = <PINMUX_GPIO45__FUNC_GPIO45>;
			slew-rate = <1>;
			output-high;
		};
	};

	mtkfb_pins_lcm_rst_out0_gpio: lcm_rst_out0_gpio {
		pins_cmd_dat {
			pinmux = <PINMUX_GPIO45__FUNC_GPIO45>;
			slew-rate = <1>;
			output-low;
		};
	};

	mtkfb_pins_lcm_dsi_te: lcm_dsi_te {
		pins_cmd_dat {
			pinmux = <PINMUX_GPIO44__FUNC_DSI_TE>;
		};
	};
};

/*&mtkfb {
	pinctrl-names =
		"lcm_rst_out1_gpio", "lcm_rst_out0_gpio",
		"mode_te_te";
	pinctrl-0 = <&mtkfb_pins_lcm_rst_out1_gpio>;
	pinctrl-1 = <&mtkfb_pins_lcm_rst_out0_gpio>;
	pinctrl-2 = <&mtkfb_pins_lcm_dsi_te>;
	status = "okay";
};*/
/* Hao.Liang@ODM_WT.MM.Display.Lcd, 2019/9/25, LCD bringup */
/* DISPSYS GPIO standardization */
&mtkfb {
        pinctrl-names = "lcm_rst_out0_gpio", "lcm_rst_out1_gpio", "lcd_bias_enp0_gpio", "lcd_bias_enp1_gpio",
			"lcd_bias_enn0_gpio", "lcd_bias_enn1_gpio", "lcd_vddio18_en0_gpio", "lcd_vddio18_en1_gpio";

	pinctrl-0 = <&mtkfb_pins_lcm_reset0>;
	pinctrl-1 = <&mtkfb_pins_lcm_reset1>;
	pinctrl-2 = <&mtkfb_pins_lcd_bias_enp0>;
	pinctrl-3 = <&mtkfb_pins_lcd_bias_enp1>;
	pinctrl-4 = <&mtkfb_pins_lcd_bias_enn0>;
	pinctrl-5 = <&mtkfb_pins_lcd_bias_enn1>;
	//pinctrl-6 = <&mtkfb_pins_lcd_vddio18_en0>;
	//pinctrl-7 = <&mtkfb_pins_lcd_vddio18_en1>;
        status = "okay";
};

&pio {
        mtkfb_pins_lcm_reset0: lcm_rst_out0_gpio {
                pins_cmd_dat {
                        pinmux = <PINMUX_GPIO45__FUNC_GPIO45>;
                        slew-rate = <1>;
                        output-low;
                };
        };
        mtkfb_pins_lcm_reset1: lcm_rst_out1_gpio {
                pins_cmd_dat {
                        pinmux = <PINMUX_GPIO45__FUNC_GPIO45>;
                        slew-rate = <1>;
                        output-high;
                };
        };

	mtkfb_pins_lcd_bias_enp0: lcd_bias_enp0_gpio {
                pins_cmd_dat {
                        pinmux = <PINMUX_GPIO169__FUNC_GPIO169>;
                        slew-rate = <1>;
                        output-low;
                };
        };
	mtkfb_pins_lcd_bias_enp1: lcd_bias_enp1_gpio {
                pins_cmd_dat {
                        pinmux = <PINMUX_GPIO169__FUNC_GPIO169>;
                        slew-rate = <1>;
                        output-high;
                };
        };

	mtkfb_pins_lcd_bias_enn0: lcd_bias_enn0_gpio {
                pins_cmd_dat {
                        pinmux = <PINMUX_GPIO165__FUNC_GPIO165>;
                        slew-rate = <1>;
                        output-low;
                };
        };
	mtkfb_pins_lcd_bias_enn1: lcd_bias_enn1_gpio {
                pins_cmd_dat {
                        pinmux = <PINMUX_GPIO165__FUNC_GPIO165>;
                        slew-rate = <1>;
                        output-high;
                };
        };

/*	mtkfb_pins_lcd_vddio18_en0: lcd_vddio18_en0_gpio {
                pins_cmd_dat {
                        pinmux = <PINMUX_GPIO170__FUNC_GPIO170>;
                        slew-rate = <1>;
                        output-low;
                };
        };
	mtkfb_pins_lcd_vddio18_en1: lcd_vddio18_en1_gpio {
                pins_cmd_dat {
                        pinmux = <PINMUX_GPIO170__FUNC_GPIO170>;
                        slew-rate = <1>;
                        output-high;
                };
        };*/
};
/* Hao.Liang@ODM_WT.MM.Display.Lcd, 2019/9/25, LCD bringup */
/* DISPSYS GPIO standardization end*/

/*Shouli.Wang@ODM_WT.BSP.CHG 2019/9/25, charger bringup start*/
&bat_gm30 {
		io-channels = <&auxadc 2>;
		io-channel-names = "batteryID-channel";	
};
#include "rt9471_single.dtsi"
/*Shouli.Wang@ODM_WT.BSP.CHG 2019/9/25, charger bringup end*/
//#ifdef ODM_WT_EDIT
/*Shouli.Wang@ODM_WT.BSP.CHG 2019/10/07, modify monet charger params*/
&charger {
	ac_charger_input_current = <2000000>;
	ac_charger_current = <2000000>;
	/delete-node/ enable_type_c;
};
//#endif /*ODM_WT_EDIT*/

//#ifdef ODM_WT_EDIT
//Mingyao.Xie@ODM_WT.BSP.Storage.Usb, 2018/08/07, Modify for OTG
&otg_iddig	{
		compatible = "mediatek,usb_iddig_bi_eint";
		interrupt-parent = <&pio>;
		interrupts = <147 IRQ_TYPE_LEVEL_LOW 147 0>;
		pinctrl-names ="otg_iddg_high", "otg_gpio_low";
		pinctrl-0 = <&otg_iddg_high>;
		pinctrl-1 = <&otg_gpio_low>;
		status = "okay";

	};

&pio {
    otg_iddg_high: otg_iddg_high {
        pins_cmd_dat {
            pinmux = <PINMUX_GPIO41__FUNC_IDDIG>;
        };
    };
    otg_gpio_low: otg_gpio_low {
        pins_cmd_dat {
            pinmux = <PINMUX_GPIO41__FUNC_GPIO41>;
            slew-rate = <1>;
            input-low;
        };
    };
};
//#endif

//#ifdef ODM_WT_EDIT
/*Shouli.Wang@ODM_WT.BSP.CHG 2019/12/03, add for key function compatible*/
&keypad {
	mediatek,kpd-sw-rstkey_1  = <115>;
	mediatek,kpd-hw-init-map_1 = <0 114 0 0 0 0 0 0 0 0 0 0 0 0 0 0 0 0 0 0 0 0 0 0 0 0 0 0 0 0 0 0 0 0 0 0 0 0 0 0 0 0 0 0 0 0 0 0 0 0 0 0 0 0 0 0 0 0 0 0 0 0 0 0 0 0 0 0 0 0 0 0 >;
};
//#endif /*ODM_WT_EDIT*/

#include "mediatek/oppo6769_19741/cust.dtsi"
#include "mediatek/cust_mt6768_camera.dtsi"
/*End of this file, DO NOT ADD ANYTHING HERE*/
